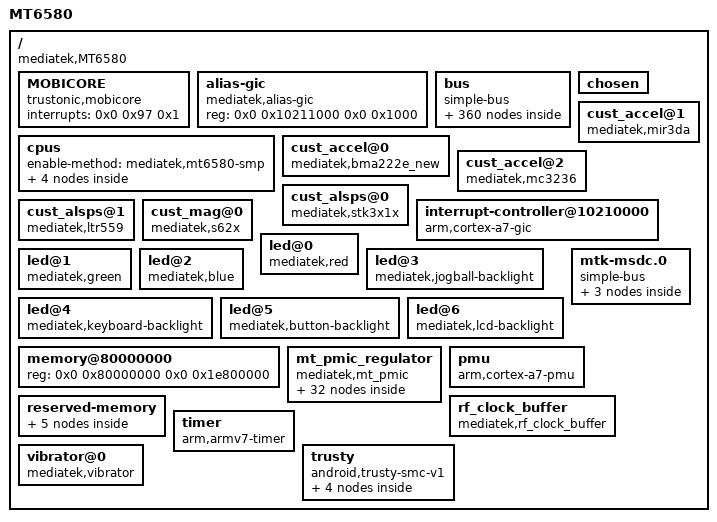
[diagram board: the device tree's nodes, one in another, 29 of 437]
/dts-v1/;

/ {
	#address-cells = <0x2>;
	#size-cells = <0x2>;
	compatible = "mediatek,MT6580";
	interrupt-parent = <0x1>;
	model = "MT6580";

	MOBICORE {
		compatible = "trustonic,mobicore";
		interrupts = <0x0 0x97 0x1>;
	};

	alias-gic {
		compatible = "mediatek,alias-gic";
		reg = <0x0 0x10211000 0x0 0x1000>;
	};

	bus {
		#address-cells = <0x1>;
		#size-cells = <0x1>;
		compatible = "simple-bus";
		ranges = <0x0 0x0 0x0 0xffffffff>;

		AES@0x1000E000 {
			compatible = "mediatek,AES";
			reg = <0x1000e000 0x1000>;
		};

		AHB_MOM@0x11150000 {
			compatible = "mediatek,AHB_MOM";
			reg = <0x11150000 0x10000>;
		};

		APMIXED@0x10018000 {
			compatible = "mediatek,APMIXED";
			reg = <0x10018000 0x1000>;
		};

		APXGPT@0x10008000 {
			clock-frequency = <0xc65d40>;
			compatible = "mediatek,APXGPT";
			interrupts = <0x0 0x5c 0x8>;
			reg = <0x10008000 0x1000>;
		};

		AP_DMA_UART0_RX@0x11000500 {
			compatible = "mediatek,AP_DMA_UART0_RX";
			interrupts = <0x0 0x39 0x8>;
			reg = <0x11000500 0x80>;
		};

		AP_DMA_UART0_TX@0x11000480 {
			compatible = "mediatek,AP_DMA_UART0_TX";
			interrupts = <0x0 0x38 0x8>;
			reg = <0x11000480 0x80>;
		};

		AP_DMA_UART1_RX@0x11000600 {
			compatible = "mediatek,AP_DMA_UART1_RX";
			interrupts = <0x0 0x3b 0x8>;
			reg = <0x11000600 0x80>;
		};

		AP_DMA_UART1_TX@0x11000580 {
			compatible = "mediatek,AP_DMA_UART1_TX";
			interrupts = <0x0 0x3a 0x8>;
			reg = <0x11000580 0x80>;
		};

		AP_UART0@0x11005000 {
			cell-index = <0x0>;
			compatible = "mediatek,AP_UART0";
			interrupts = <0x0 0x2c 0x8>;
			reg = <0x11005000 0x1000>;
		};

		AP_UART1@0x11006000 {
			cell-index = <0x1>;
			compatible = "mediatek,AP_UART1";
			interrupts = <0x0 0x2d 0x8>;
			reg = <0x11006000 0x1000>;
		};

		BAT_NOTIFY {
			compatible = "mediatek,bat_notify";
		};

		BTCVSD@0x18000000 {
			compatible = "mediatek,audio_bt_cvsd";
			interrupts = <0x0 0x99 0x8>;
			offset = <0xc00 0x2 0xfd0 0xfd4 0xfd8>;
			reg = <0x10001000 0x1000 0x18000000 0x10000 0x18080000 0x8000>;
		};

		CAM_0@0x15004000 {
			compatible = "mediatek,CAM_0";
			interrupts = <0x0 0x8b 0x8>;
			reg = <0x15004000 0x1000>;
		};

		CAM_1@0x15005000 {
			compatible = "mediatek,CAM_1";
			reg = <0x15005000 0x1000>;
		};

		DBGSYS_CPU@0x10160000 {
			compatible = "mediatek,DBGSYS_CPU";
			reg = <0x10160000 0x20000>;
		};

		DBGSYS_CTI@0x10112000 {
			compatible = "mediatek,DBGSYS_CTI";
			reg = <0x10112000 0x1000>;
		};

		DBGSYS_DAPROM@0x10110000 {
			compatible = "mediatek,DBGSYS_DAPROM";
			reg = <0x10110000 0x1000>;
		};

		DBGSYS_DEM@0x1011A000 {
			compatible = "mediatek,DBGSYS_DEM";
			reg = <0x1011a000 0x1000>;
		};

		DBGSYS_MDSYS@0x10120000 {
			compatible = "mediatek,DBGSYS_MDSYS";
			reg = <0x10120000 0x10000>;
		};

		DDRPHY@0x10208000 {
			compatible = "mediatek,DDRPHY";
			reg = <0x10208000 0x1000>;
		};

		DEVAPC@0x10204000 {
			compatible = "mediatek,DEVAPC";
			interrupts = <0x0 0x4a 0x8>;
			reg = <0x10204000 0x1000>;
		};

		DEVAPC_AO@0x10010000 {
			compatible = "mediatek,DEVAPC_AO";
			reg = <0x10010000 0x1000>;
		};

		DISPSYS@0x14007000 {
			compatible = "mediatek,DISPSYS";
			interrupts = <0x0 0x0 0x8 0x0 0x77 0x8 0x0 0x0 0x8 0x0 0x79 0x8 0x0 0x0 0x8 0x0 0x7b 0x8 0x0 0x7c 0x8 0x0 0x0 0x8 0x0 0x7e 0x8 0x0 0x7f 0x8 0x0 0x80 0x8 0x0 0x0 0x8 0x0 0x82 0x8 0x0 0x0 0x8 0x0 0x0 0x8 0x0 0x70 0x8 0x0 0x0 0x8 0x0 0x0 0x8 0x0 0x0 0x8>;
			reg = <0x14000000 0x1000 0x14007000 0x1000 0x14008000 0x1000 0x14009000 0x1000 0x1400a000 0x1000 0x1400b000 0x1000 0x1400c000 0x1000 0x1400d000 0x1000 0x1400e000 0x1000 0x1400f000 0x1000 0x14010000 0x1000 0x14011000 0x1000 0x14012000 0x1000 0x14013000 0x1000 0x1100f000 0x1000 0x14015000 0x1000 0x14016000 0x1000 0x14017000 0x1000 0x14018000 0x1000>;
		};

		DISP_AAL@0x1400E000 {
			compatible = "mediatek,DISP_AAL";
			interrupts = <0x0 0x7e 0x8>;
			reg = <0x1400e000 0x1000>;
		};

		DISP_CCORR@0x1400D000 {
			compatible = "mediatek,DISP_CCORR";
			reg = <0x1400d000 0x1000>;
		};

		DISP_COLOR@0x1400C000 {
			compatible = "mediatek,DISP_COLOR";
			interrupts = <0x0 0x7c 0x8>;
			reg = <0x1400c000 0x1000>;
		};

		DISP_DITHER@0x14010000 {
			compatible = "mediatek,DISP_DITHER";
			interrupts = <0x0 0x80 0x8>;
			reg = <0x14010000 0x1000>;
		};

		DISP_GAMMA@0x1400F000 {
			compatible = "mediatek,DISP_GAMMA";
			interrupts = <0x0 0x7f 0x8>;
			reg = <0x1400f000 0x1000>;
		};

		DISP_OVL0@0x14007000 {
			compatible = "mediatek,DISP_OVL0";
			interrupts = <0x0 0x77 0x8>;
			reg = <0x14007000 0x1000>;
		};

		DISP_OVL1@0x14008000 {
			compatible = "mediatek,DISP_OVL1";
			reg = <0x14008000 0x1000>;
		};

		DISP_PWM@0x1100F000 {
			compatible = "mediatek,DISP_PWM";
			interrupts = <0x0 0x21 0x8>;
			reg = <0x1100f000 0x1000>;
		};

		DISP_RDMA0@0x14009000 {
			compatible = "mediatek,DISP_RDMA0";
			interrupts = <0x0 0x79 0x8>;
			reg = <0x14009000 0x1000>;
		};

		DISP_RDMA1@0x1400A000 {
			compatible = "mediatek,DISP_RDMA1";
			reg = <0x1400a000 0x1000>;
		};

		DISP_UFOE@0x14011000 {
			compatible = "mediatek,DISP_UFOE";
			reg = <0x14011000 0x1000>;
		};

		DISP_WDMA@0x1400B000 {
			compatible = "mediatek,DISP_WDMA";
			interrupts = <0x0 0x7b 0x8>;
			reg = <0x1400b000 0x1000>;
		};

		DPI@0x14013000 {
			compatible = "mediatek,DPI";
			reg = <0x14013000 0x1000>;
		};

		DRAMC0@0x10207000 {
			compatible = "mediatek,DRAMC0";
			reg = <0x10207000 0x1000>;
		};

		DRAMC_NAO@0x10206000 {
			compatible = "mediatek,DRAMC_NAO";
			reg = <0x10206000 0x1000>;
		};

		DSI@0x14012000 {
			compatible = "mediatek,DSI";
			reg = <0x14012000 0x1000>;
		};

		EFUSEC@0x10009000 {
			compatible = "mediatek,EFUSEC";
			reg = <0x10009000 0x1000>;
		};

		EMI@0x10205000 {
			compatible = "mediatek,EMI";
			interrupts = <0x0 0x4c 0x4>;
			reg = <0x10205000 0x1000>;
		};

		FHCTL@0x11004000 {
			compatible = "mediatek,FHCTL";
			reg = <0x11004000 0x1000>;
		};

		G3D_CONFIG@0x13000000 {
			compatible = "mediatek,G3D_CONFIG";
			reg = <0x13000000 0x1000>;
		};

		IMGSYS_CONFIG@0x15000000 {
			compatible = "mediatek,IMGSYS_CONFIG";
			reg = <0x15000000 0x1000>;
		};

		INFRACFG@0x10201000 {
			compatible = "mediatek,INFRACFG";
			reg = <0x10201000 0x1000>;
		};

		INFRACFG_AO@0x10001000 {
			compatible = "mediatek,INFRACFG_AO";
			reg = <0x10001000 0x1000>;
		};

		INFRA_MBIST@0x10012000 {
			compatible = "mediatek,INFRA_MBIST";
			reg = <0x10012000 0x1000>;
		};

		IOCFG_B@0x10015000 {
			compatible = "mediatek,IOCFG_B";
			reg = <0x10015000 0x1000>;
		};

		IOCFG_L@0x10016000 {
			compatible = "mediatek,IOCFG_L";
			reg = <0x10016000 0x1000>;
		};

		IOCFG_R@0x10017000 {
			compatible = "mediatek,IOCFG_R";
			reg = <0x10017000 0x1000>;
		};

		IOCFG_T@0x10014000 {
			compatible = "mediatek,IOCFG_T";
			reg = <0x10014000 0x1000>;
		};

		ISPSYS@0x15000000 {
			compatible = "mediatek,ISPSYS";
			interrupts = <0x0 0x8e 0x8 0x0 0x8b 0x8>;
			reg = <0x15004000 0x9000 0x15000000 0x10000 0x10011000 0x4000 0x10017000 0x1000>;
		};

		ISP_PIPEM@0x15000000 {
			compatible = "mediatek,ISP_PIPEM";
		};

		ISP_SYSR@0x15000000 {
			compatible = "mediatek,ISP_SYSR";
		};

		MALI@0x13010000 {
			compatible = "mediatek,MALI";
			reg = <0x13010000 0x10000>;
		};

		MCUCFG@0x10200000 {
			compatible = "mediatek,MCUCFG";
			reg = <0x10200000 0x1000>;
		};

		MCUCFG_BIU@0x1020D000 {
			compatible = "mediatek,MCUCFG_BIU";
			reg = <0x1020d000 0x1000>;
		};

		MCUSYS_CFGREG@0x1020000 {
			compatible = "mediatek,MCUSYS_CFGREG_BASE";
			reg = <0x1020000 0x200>;
		};

		MDI@0x11160000 {
			compatible = "mediatek,MDI";
			reg = <0x11160000 0x10000>;
		};

		MIPI_CONFG@0x10011000 {
			compatible = "mediatek,MIPI_CONFG";
			reg = <0x10011000 0x1000>;
		};

		MIPI_TX_CONFIG@0x14018000 {
			compatible = "mediatek,MIPI_TX_CONFIG";
			reg = <0x14018000 0x1000>;
		};

		MM_MUTEX@0x14015000 {
			compatible = "mediatek,MM_MUTEX";
			interrupts = <0x0 0x70 0x8>;
			reg = <0x14015000 0x1000>;
		};

		NFI@0x11001000 {
			compatible = "mediatek,NFI";
			interrupts = <0x0 0x2f 0x8>;
			reg = <0x11001000 0x1000>;
		};

		NFIECC@0x11002000 {
			compatible = "mediatek,NFIECC";
			interrupts = <0x0 0x2e 0x8>;
			reg = <0x11002000 0x1000>;
		};

		PERICFG@0x10003000 {
			compatible = "mediatek,PERICFG";
			reg = <0x10003000 0x1000>;
		};

		PTP_FSM@0x1100D000 {
			compatible = "mediatek,PTP_FSM";
			interrupts = <0x0 0x2b 0x8>;
			reg = <0x1100d000 0x1000>;
		};

		PWM@0x11008000 {
			compatible = "mediatek,PWM";
			interrupts = <0x0 0x24 0x8>;
			reg = <0x11008000 0x1000>;
		};

		PWRAP@0x1000F000 {
			compatible = "mediatek,PWRAP";
			interrupts = <0x0 0x6c 0x0>;
			reg = <0x1000f000 0x1000>;
		};

		RESERVED@0x10004000 {
			compatible = "mediatek,RESERVED";
			reg = <0x10004000 0x1000>;
		};

		RESERVED@0x10013000 {
			compatible = "mediatek,RESERVED";
			reg = <0x10013000 0x1000>;
		};

		SLEEP@0x10006000 {
			compatible = "mediatek,SLEEP";
			interrupts = <0x0 0x58 0x8 0x0 0x59 0x8 0x0 0x5a 0x8 0x0 0x5b 0x8>;
			reg = <0x10006000 0x1000>;
		};

		SMI_COMMON@0x14017000 {
			compatible = "mediatek,SMI_COMMON";
			reg = <0x14017000 0x1000 0x14016000 0x1000 0x15001000 0x1000>;
		};

		SMI_LARB0@0x14016000 {
			compatible = "mediatek,SMI_LARB0";
			interrupts = <0x0 0x85 0x8>;
			reg = <0x14016000 0x1000>;
		};

		SMI_LARB1@0x15001000 {
			compatible = "mediatek,SMI_LARB1";
			interrupts = <0x0 0x88 0x8>;
			reg = <0x15001000 0x1000>;
		};

		SRAMROM@0x10209000 {
			compatible = "mediatek,SRAMROM";
			reg = <0x10209000 0x1000>;
		};

		THERM_CTRL@0x1100D000 {
			compatible = "mediatek,THERM_CTRL";
			interrupts = <0x0 0x25 0x8>;
			reg = <0x1100d000 0x1000>;
		};

		TOPCKGEN@0x10000000 {
			compatible = "mediatek,TOPCKGEN";
			reg = <0x10000000 0x1000>;
		};

		TOPRGU@0x10007000 {
			compatible = "mediatek,TOPRGU";
			interrupts = <0x0 0x9d 0x2>;
			reg = <0x10007000 0x1000>;
		};

		TRNG@0x1020C000 {
			compatible = "mediatek,TRNG";
			interrupts = <0x0 0x57 0x8>;
			reg = <0x1020c000 0x1000>;
		};

		USB0@0x11100000 {
			cell-index = <0x0>;
			compatible = "mediatek,USB0";
			dma = <0x1>;
			dma_channels = <0x8>;
			drvvbus_gpio = <0x19 0x0>;
			dyn_fifo = <0x1>;
			iddig_gpio = <0x10 0x6>;
			interrupts = <0x0 0x20 0x8>;
			mode = <0x2>;
			multipoint = <0x1>;
			num_eps = <0x10>;
			pinctrl-0 = <0x1f>;
			pinctrl-1 = <0x20>;
			pinctrl-2 = <0x21>;
			pinctrl-3 = <0x22>;
			pinctrl-4 = <0x23>;
			pinctrl-5 = <0x24>;
			pinctrl-6 = <0x25>;
			pinctrl-7 = <0x26>;
			pinctrl-names = "usb_default", "iddig_irq_init", "drvvbus_init", "drvvbus_low", "drvvbus_high", "otgusden_init", "otgusben_low", "otgusben_high";
			reg = <0x11100000 0x10000 0x11110000 0x10000>;
			soft_con = <0x1>;
			status = "okay";

			usbiddig {
				compatible = "mediatek,usb_iddig_eint";
				debounce = <0x10 0x0>;
				interrupt-parent = <0xc>;
				interrupts = <0x10 0x8>;
				status = "okay";
			};
		};

		VDEC@0x1500B000 {
			compatible = "mediatek,VDEC";
			interrupts = <0x0 0x89 0x8>;
			reg = <0x1500b000 0x1000>;
		};

		VENC@0x15009000 {
			compatible = "mediatek,VENC";
			interrupts = <0x0 0x8a 0x8>;
			reg = <0x15009000 0x1000>;
		};

		WIFI@0x180F0000 {
			compatible = "mediatek,WIFI";
			interrupts = <0x0 0x9b 0x8>;
			reg = <0x180f0000 0x5c>;
		};

		accdet {
			accdet-mic-mode = <0x1>;
			accdet-mic-vol = <0x7>;
			accdet-plugout-debounce = <0x14>;
			compatible = "mediatek,mt6580-accdet";
			debounce = <0x4 0x3e800>;
			headset-four-key-threshold = <0x0 0x3c 0x7e 0xc9 0x1c2>;
			headset-mode-setting = <0x500 0x200 0x1 0x1f0 0x800 0x800 0x20>;
			headset-three-key-threshold = <0x0 0x5a 0xf0 0x1f4>;
			interrupt-parent = <0xc>;
			interrupts = <0x4 0x8>;
			pinctrl-0 = <0x15>;
			pinctrl-1 = <0x16>;
			pinctrl-names = "default", "state_eint_as_int";
			status = "okay";
		};

		activity@0 {
			compatible = "mediatek,activity";
		};

		adc_hw@11003000 {
			compatible = "mediatek,mt6735-auxadc";
			interrupts = <0x0 0x23 0x2>;
			reg = <0x11003000 0x1000>;

			adc_channel@ {
				compatible = "mediatek,adc_channel";
				mediatek,temperature0 = <0x0>;
				mediatek,temperature1 = <0x1>;
				status = "okay";
			};
		};

		als {
			compatible = "mediatek, als-eint";
			debounce = <0x6 0x7d00>;
			interrupt-parent = <0xc>;
			interrupts = <0x6 0x8>;
			status = "okay";
		};

		als_ps@0 {
			compatible = "mediatek,als_ps";
			pinctrl-0 = <0x47>;
			pinctrl-1 = <0x48>;
			pinctrl-names = "pin_default", "pin_cfg";
			status = "okay";
		};

		ap_ccif0@1000C000 {
			compatible = "mediatek,ap_ccif0";
			interrupts = <0x0 0x5d 0x8 0x0 0x98 0x2>;
			mediatek,ccif_capability = <0x2>;
			mediatek,md_smem_size = <0x200000>;
			reg = <0x1000c000 0x1000 0x1000d000 0x1000>;
		};

		audio@11140000 {
			compatible = "mediatek,audio";
			interrupts = <0x0 0x50 0x8>;
			reg = <0x11140000 0x10000>;
		};

		barometer@0 {
			compatible = "mediatek,barometer";
		};

		bat_comm {
			ac_charger_current = <0x15f90>;
			bat_low_temp_protect_enable = <0x0>;
			charging_host_charger_current = <0xfde8>;
			compatible = "mediatek,battery";
			fg_meter_resistance = <0x0>;
			high_battery_voltage_support = <0x0>;
			non_std_ac_charger_current = <0xfde8>;
			npercent_tracking_time = <0x14>;
			onehundred_percent_tracking_time = <0xa>;
			r_bat_sense = <0x4>;
			r_charger_1 = <0x14a>;
			r_charger_2 = <0x27>;
			r_i_sense = <0x4>;
			sync_to_real_tracking_time = <0x3c>;
			temperature_t = <0xff>;
			temperature_t0 = <0x6e>;
			temperature_t1 = <0x0>;
			temperature_t2 = <0x19>;
			temperature_t3 = <0x32>;
			usb_charger_current = <0xfde8>;
			v_0percent_tracking = <0xd48>;
			v_charger_enable = <0x0>;
			v_charger_max = <0x1964>;
			v_charger_min = <0x1130>;
		};

		bat_meter {
			aging_tuning_value = <0x67>;
			batt_temperature_table = <0xffffffec 0x10a8d 0xfffffff1 0xd192 0xfffffff6 0xa60a 0xfffffffb 0x8464 0x0 0x6a53 0x5 0x5605 0xa 0x4606 0xf 0x3952 0x14 0x2f31 0x19 0x2710 0x1e 0x207b 0x23 0x1b24 0x28 0x16ca 0x2d 0x1335 0x32 0x1041 0x37 0xdcf 0x3c 0xbc6>;
			batt_temperature_table_num = <0x11>;
			battery_profile_t0 = <0x0 0x1048 0x1 0x102b 0x2 0x1018 0x3 0x100a 0x4 0xffe 0x5 0xff5 0x6 0xfec 0x7 0xfe5 0x8 0xfdf 0x9 0xfd8 0xa 0xfd3 0xb 0xfce 0xc 0xfca 0xd 0xfc5 0xe 0xfc1 0xf 0xfbd 0x10 0xfb9 0x11 0xfb5 0x12 0xfb1 0x13 0xfad 0x14 0xfaa 0x15 0xfa5 0x16 0xfa0 0x17 0xf9c 0x18 0xf98 0x19 0xf93 0x1a 0xf8e 0x1b 0xf89 0x1c 0xf83 0x1d 0xf7e 0x1e 0xf79 0x1f 0xf73 0x20 0xf6d 0x21 0xf67 0x22 0xf61 0x23 0xf5a 0x24 0xf54 0x25 0xf4d 0x26 0xf46 0x27 0xf3f 0x28 0xf3a 0x29 0xf33 0x2a 0xf2d 0x2b 0xf27 0x2c 0xf21 0x2d 0xf1b 0x2e 0xf16 0x2f 0xf11 0x30 0xf0c 0x31 0xf07 0x33 0xf01 0x34 0xefe 0x35 0xef9 0x36 0xef4 0x37 0xeef 0x38 0xeeb 0x39 0xee7 0x3a 0xee2 0x3b 0xedd 0x3c 0xed8 0x3d 0xed4 0x3e 0xecf 0x3f 0xec9 0x40 0xec4 0x41 0xebf 0x42 0xeba 0x43 0xeb4 0x44 0xeae 0x45 0xea7 0x46 0xea1 0x47 0xe99 0x48 0xe92 0x49 0xe8a 0x4a 0xe83 0x4b 0xe7a 0x4c 0xe71 0x4d 0xe68 0x4e 0xe60 0x4f 0xe57 0x50 0xe4f 0x51 0xe46 0x52 0xe3e 0x53 0xe36 0x54 0xe2f 0x55 0xe27 0x56 0xe20 0x57 0xe18 0x58 0xe12 0x59 0xe0b 0x5a 0xe04 0x5b 0xdfd 0x5c 0xdf6 0x5d 0xdef 0x5e 0xde8 0x5f 0xde1 0x60 0xdd9 0x61 0xdd0 0x62 0xdc8 0x63 0xdc0 0x64 0xdb5 0x65 0xdac>;
			battery_profile_t0_num = <0x65>;
			battery_profile_t1 = <0x0 0x1048 0x1 0x102b 0x2 0x1018 0x3 0x100a 0x4 0xffe 0x5 0xff5 0x6 0xfec 0x7 0xfe5 0x8 0xfdf 0x9 0xfd8 0xa 0xfd3 0xb 0xfce 0xc 0xfca 0xd 0xfc5 0xe 0xfc1 0xf 0xfbd 0x10 0xfb9 0x11 0xfb5 0x12 0xfb1 0x13 0xfad 0x14 0xfaa 0x15 0xfa5 0x16 0xfa0 0x17 0xf9c 0x18 0xf98 0x19 0xf93 0x1a 0xf8e 0x1b 0xf89 0x1c 0xf83 0x1d 0xf7e 0x1e 0xf79 0x1f 0xf73 0x20 0xf6d 0x21 0xf67 0x22 0xf61 0x23 0xf5a 0x24 0xf54 0x25 0xf4d 0x26 0xf46 0x27 0xf3f 0x28 0xf3a 0x29 0xf33 0x2a 0xf2d 0x2b 0xf27 0x2c 0xf21 0x2d 0xf1b 0x2e 0xf16 0x2f 0xf11 0x30 0xf0c 0x31 0xf07 0x33 0xf01 0x34 0xefe 0x35 0xef9 0x36 0xef4 0x37 0xeef 0x38 0xeeb 0x39 0xee7 0x3a 0xee2 0x3b 0xedd 0x3c 0xed8 0x3d 0xed4 0x3e 0xecf 0x3f 0xec9 0x40 0xec4 0x41 0xebf 0x42 0xeba 0x43 0xeb4 0x44 0xeae 0x45 0xea7 0x46 0xea1 0x47 0xe99 0x48 0xe92 0x49 0xe8a 0x4a 0xe83 0x4b 0xe7a 0x4c 0xe71 0x4d 0xe68 0x4e 0xe60 0x4f 0xe57 0x50 0xe4f 0x51 0xe46 0x52 0xe3e 0x53 0xe36 0x54 0xe2f 0x55 0xe27 0x56 0xe20 0x57 0xe18 0x58 0xe12 0x59 0xe0b 0x5a 0xe04 0x5b 0xdfd 0x5c 0xdf6 0x5d 0xdef 0x5e 0xde8 0x5f 0xde1 0x60 0xdd9 0x61 0xdd0 0x62 0xdc8 0x63 0xdc0 0x64 0xdb5 0x65 0xdac>;
			battery_profile_t1_num = <0x65>;
			battery_profile_t2 = <0x0 0x1048 0x1 0x102b 0x2 0x1018 0x3 0x100a 0x4 0xffe 0x5 0xff5 0x6 0xfec 0x7 0xfe5 0x8 0xfdf 0x9 0xfd8 0xa 0xfd3 0xb 0xfce 0xc 0xfca 0xd 0xfc5 0xe 0xfc1 0xf 0xfbd 0x10 0xfb9 0x11 0xfb5 0x12 0xfb1 0x13 0xfad 0x14 0xfaa 0x15 0xfa5 0x16 0xfa0 0x17 0xf9c 0x18 0xf98 0x19 0xf93 0x1a 0xf8e 0x1b 0xf89 0x1c 0xf83 0x1d 0xf7e 0x1e 0xf79 0x1f 0xf73 0x20 0xf6d 0x21 0xf67 0x22 0xf61 0x23 0xf5a 0x24 0xf54 0x25 0xf4d 0x26 0xf46 0x27 0xf3f 0x28 0xf3a 0x29 0xf33 0x2a 0xf2d 0x2b 0xf27 0x2c 0xf21 0x2d 0xf1b 0x2e 0xf16 0x2f 0xf11 0x30 0xf0c 0x31 0xf07 0x33 0xf01 0x34 0xefe 0x35 0xef9 0x36 0xef4 0x37 0xeef 0x38 0xeeb 0x39 0xee7 0x3a 0xee2 0x3b 0xedd 0x3c 0xed8 0x3d 0xed4 0x3e 0xecf 0x3f 0xec9 0x40 0xec4 0x41 0xebf 0x42 0xeba 0x43 0xeb4 0x44 0xeae 0x45 0xea7 0x46 0xea1 0x47 0xe99 0x48 0xe92 0x49 0xe8a 0x4a 0xe83 0x4b 0xe7a 0x4c 0xe71 0x4d 0xe68 0x4e 0xe60 0x4f 0xe57 0x50 0xe4f 0x51 0xe46 0x52 0xe3e 0x53 0xe36 0x54 0xe2f 0x55 0xe27 0x56 0xe20 0x57 0xe18 0x58 0xe12 0x59 0xe0b 0x5a 0xe04 0x5b 0xdfd 0x5c 0xdf6 0x5d 0xdef 0x5e 0xde8 0x5f 0xde1 0x60 0xdd9 0x61 0xdd0 0x62 0xdc8 0x63 0xdc0 0x64 0xdb5 0x65 0xdac>;
			battery_profile_t2_num = <0x65>;
			battery_profile_t3 = <0x0 0x1048 0x1 0x102b 0x2 0x1018 0x3 0x100a 0x4 0xffe 0x5 0xff5 0x6 0xfec 0x7 0xfe5 0x8 0xfdf 0x9 0xfd8 0xa 0xfd3 0xb 0xfce 0xc 0xfca 0xd 0xfc5 0xe 0xfc1 0xf 0xfbd 0x10 0xfb9 0x11 0xfb5 0x12 0xfb1 0x13 0xfad 0x14 0xfaa 0x15 0xfa5 0x16 0xfa0 0x17 0xf9c 0x18 0xf98 0x19 0xf93 0x1a 0xf8e 0x1b 0xf89 0x1c 0xf83 0x1d 0xf7e 0x1e 0xf79 0x1f 0xf73 0x20 0xf6d 0x21 0xf67 0x22 0xf61 0x23 0xf5a 0x24 0xf54 0x25 0xf4d 0x26 0xf46 0x27 0xf3f 0x28 0xf3a 0x29 0xf33 0x2a 0xf2d 0x2b 0xf27 0x2c 0xf21 0x2d 0xf1b 0x2e 0xf16 0x2f 0xf11 0x30 0xf0c 0x31 0xf07 0x33 0xf01 0x34 0xefe 0x35 0xef9 0x36 0xef4 0x37 0xeef 0x38 0xeeb 0x39 0xee7 0x3a 0xee2 0x3b 0xedd 0x3c 0xed8 0x3d 0xed4 0x3e 0xecf 0x3f 0xec9 0x40 0xec4 0x41 0xebf 0x42 0xeba 0x43 0xeb4 0x44 0xeae 0x45 0xea7 0x46 0xea1 0x47 0xe99 0x48 0xe92 0x49 0xe8a 0x4a 0xe83 0x4b 0xe7a 0x4c 0xe71 0x4d 0xe68 0x4e 0xe60 0x4f 0xe57 0x50 0xe4f 0x51 0xe46 0x52 0xe3e 0x53 0xe36 0x54 0xe2f 0x55 0xe27 0x56 0xe20 0x57 0xe18 0x58 0xe12 0x59 0xe0b 0x5a 0xe04 0x5b 0xdfd 0x5c 0xdf6 0x5d 0xdef 0x5e 0xde8 0x5f 0xde1 0x60 0xdd9 0x61 0xdd0 0x62 0xdc8 0x63 0xdc0 0x64 0xdb5 0x65 0xdac>;
			battery_profile_t3_num = <0x65>;
			car_tune_value = <0x64>;
			change_tracking_point = <0x1>;
			close_poweroff_wakeup_period = <0x1e>;
			compatible = "mediatek,bat_meter";
			current_detect_r_fg = <0xa>;
			cust_hw_cc = <0x0>;
			cust_poweron_delta_capacity_tolrance = <0x28>;
			cust_poweron_delta_hw_sw_ocv_capacity_tolrance = <0xa>;
			cust_poweron_delta_vbat_tolrance = <0x1e>;
			cust_poweron_low_capacity_tolrance = <0x5>;
			cust_poweron_max_vbat_tolrance = <0x5a>;
			cust_r_fg_offset = <0x0>;
			cust_r_sense = <0x64>;
			cust_tracking_point = <0x1>;
			fg_vbat_average_size = <0x12>;
			fixed_tbat_25 = <0x0>;
			low_power_wakeup_period = <0x12c>;
			minerroroffset = <0x3e8>;
			normal_wakeup_period = <0x1518>;
			oam_d5 = <0x1>;
			ocv_board_compesate = <0x0>;
			q_max_neg_10 = <0x1162>;
			q_max_neg_10_h_current = <0x10cc>;
			q_max_pos_0 = <0x1162>;
			q_max_pos_0_h_current = <0x10cc>;
			q_max_pos_25 = <0x1162>;
			q_max_pos_25_h_current = <0x10cc>;
			q_max_pos_50 = <0x1162>;
			q_max_pos_50_h_current = <0x10cc>;
			r_fg_board_base = <0x3e8>;
			r_fg_board_slope = <0x3e8>;
			r_fg_value = <0x0>;
			r_profile_t0 = <0x46 0x105c 0x46 0x102b 0x46 0x1018 0x46 0x100a 0x46 0xffe 0x46 0xff5 0x46 0xfec 0x46 0xfe5 0x46 0xfdf 0x46 0xfd8 0x46 0xfd3 0x46 0xfce 0x46 0xfca 0x46 0xfc5 0x46 0xfc1 0x46 0xfbd 0x46 0xfb9 0x46 0xfb5 0x46 0xfb1 0x46 0xfad 0x46 0xfaa 0x46 0xfa5 0x46 0xfa0 0x46 0xf9c 0x46 0xf98 0x46 0xf93 0x46 0xf8e 0x46 0xf89 0x46 0xf83 0x46 0xf7e 0x46 0xf79 0x46 0xf73 0x46 0xf6d 0x46 0xf67 0x46 0xf61 0x46 0xf5a 0x46 0xf54 0x46 0xf4d 0x46 0xf46 0x46 0xf3f 0x46 0xf3a 0x46 0xf33 0x46 0xf2d 0x46 0xf27 0x46 0xf21 0x46 0xf1b 0x46 0xf16 0x46 0xf11 0x46 0xf0c 0x46 0xf07 0x46 0xf01 0x46 0xefe 0x46 0xef9 0x46 0xef4 0x46 0xeef 0x46 0xeeb 0x46 0xee7 0x46 0xee2 0x46 0xedd 0x46 0xed8 0x46 0xed4 0x46 0xecf 0x46 0xec9 0x46 0xec4 0x46 0xebf 0x46 0xeba 0x46 0xeb4 0x46 0xeae 0x46 0xea7 0x46 0xea1 0x46 0xe99 0x46 0xe92 0x46 0xe8a 0x46 0xe83 0x46 0xe7a 0x46 0xe71 0x46 0xe68 0x46 0xe60 0x46 0xe57 0x46 0xe4f 0x46 0xe46 0x46 0xe3e 0x46 0xe36 0x46 0xe2f 0x46 0xe27 0x46 0xe20 0x46 0xe18 0x46 0xe12 0x46 0xe0b 0x46 0xe04 0x46 0xdfd 0x46 0xdf6 0x46 0xdef 0x46 0xde8 0x46 0xde1 0x46 0xdd9 0x46 0xdd0 0x46 0xdc8 0x46 0xdc0 0x46 0xdb5 0x46 0xdac>;
			r_profile_t0_num = <0x65>;
			r_profile_t1 = <0x46 0x105c 0x46 0x102b 0x46 0x1018 0x46 0x100a 0x46 0xffe 0x46 0xff5 0x46 0xfec 0x46 0xfe5 0x46 0xfdf 0x46 0xfd8 0x46 0xfd3 0x46 0xfce 0x46 0xfca 0x46 0xfc5 0x46 0xfc1 0x46 0xfbd 0x46 0xfb9 0x46 0xfb5 0x46 0xfb1 0x46 0xfad 0x46 0xfaa 0x46 0xfa5 0x46 0xfa0 0x46 0xf9c 0x46 0xf98 0x46 0xf93 0x46 0xf8e 0x46 0xf89 0x46 0xf83 0x46 0xf7e 0x46 0xf79 0x46 0xf73 0x46 0xf6d 0x46 0xf67 0x46 0xf61 0x46 0xf5a 0x46 0xf54 0x46 0xf4d 0x46 0xf46 0x46 0xf3f 0x46 0xf3a 0x46 0xf33 0x46 0xf2d 0x46 0xf27 0x46 0xf21 0x46 0xf1b 0x46 0xf16 0x46 0xf11 0x46 0xf0c 0x46 0xf07 0x46 0xf01 0x46 0xefe 0x46 0xef9 0x46 0xef4 0x46 0xeef 0x46 0xeeb 0x46 0xee7 0x46 0xee2 0x46 0xedd 0x46 0xed8 0x46 0xed4 0x46 0xecf 0x46 0xec9 0x46 0xec4 0x46 0xebf 0x46 0xeba 0x46 0xeb4 0x46 0xeae 0x46 0xea7 0x46 0xea1 0x46 0xe99 0x46 0xe92 0x46 0xe8a 0x46 0xe83 0x46 0xe7a 0x46 0xe71 0x46 0xe68 0x46 0xe60 0x46 0xe57 0x46 0xe4f 0x46 0xe46 0x46 0xe3e 0x46 0xe36 0x46 0xe2f 0x46 0xe27 0x46 0xe20 0x46 0xe18 0x46 0xe12 0x46 0xe0b 0x46 0xe04 0x46 0xdfd 0x46 0xdf6 0x46 0xdef 0x46 0xde8 0x46 0xde1 0x46 0xdd9 0x46 0xdd0 0x46 0xdc8 0x46 0xdc0 0x46 0xdb5 0x46 0xdac>;
			r_profile_t1_num = <0x65>;
			r_profile_t2 = <0x46 0x105c 0x46 0x102b 0x46 0x1018 0x46 0x100a 0x46 0xffe 0x46 0xff5 0x46 0xfec 0x46 0xfe5 0x46 0xfdf 0x46 0xfd8 0x46 0xfd3 0x46 0xfce 0x46 0xfca 0x46 0xfc5 0x46 0xfc1 0x46 0xfbd 0x46 0xfb9 0x46 0xfb5 0x46 0xfb1 0x46 0xfad 0x46 0xfaa 0x46 0xfa5 0x46 0xfa0 0x46 0xf9c 0x46 0xf98 0x46 0xf93 0x46 0xf8e 0x46 0xf89 0x46 0xf83 0x46 0xf7e 0x46 0xf79 0x46 0xf73 0x46 0xf6d 0x46 0xf67 0x46 0xf61 0x46 0xf5a 0x46 0xf54 0x46 0xf4d 0x46 0xf46 0x46 0xf3f 0x46 0xf3a 0x46 0xf33 0x46 0xf2d 0x46 0xf27 0x46 0xf21 0x46 0xf1b 0x46 0xf16 0x46 0xf11 0x46 0xf0c 0x46 0xf07 0x46 0xf01 0x46 0xefe 0x46 0xef9 0x46 0xef4 0x46 0xeef 0x46 0xeeb 0x46 0xee7 0x46 0xee2 0x46 0xedd 0x46 0xed8 0x46 0xed4 0x46 0xecf 0x46 0xec9 0x46 0xec4 0x46 0xebf 0x46 0xeba 0x46 0xeb4 0x46 0xeae 0x46 0xea7 0x46 0xea1 0x46 0xe99 0x46 0xe92 0x46 0xe8a 0x46 0xe83 0x46 0xe7a 0x46 0xe71 0x46 0xe68 0x46 0xe60 0x46 0xe57 0x46 0xe4f 0x46 0xe46 0x46 0xe3e 0x46 0xe36 0x46 0xe2f 0x46 0xe27 0x46 0xe20 0x46 0xe18 0x46 0xe12 0x46 0xe0b 0x46 0xe04 0x46 0xdfd 0x46 0xdf6 0x46 0xdef 0x46 0xde8 0x46 0xde1 0x46 0xdd9 0x46 0xdd0 0x46 0xdc8 0x46 0xdc0 0x46 0xdb5 0x46 0xdac>;
			r_profile_t2_num = <0x65>;
			r_profile_t3 = <0x46 0x105c 0x46 0x102b 0x46 0x1018 0x46 0x100a 0x46 0xffe 0x46 0xff5 0x46 0xfec 0x46 0xfe5 0x46 0xfdf 0x46 0xfd8 0x46 0xfd3 0x46 0xfce 0x46 0xfca 0x46 0xfc5 0x46 0xfc1 0x46 0xfbd 0x46 0xfb9 0x46 0xfb5 0x46 0xfb1 0x46 0xfad 0x46 0xfaa 0x46 0xfa5 0x46 0xfa0 0x46 0xf9c 0x46 0xf98 0x46 0xf93 0x46 0xf8e 0x46 0xf89 0x46 0xf83 0x46 0xf7e 0x46 0xf79 0x46 0xf73 0x46 0xf6d 0x46 0xf67 0x46 0xf61 0x46 0xf5a 0x46 0xf54 0x46 0xf4d 0x46 0xf46 0x46 0xf3f 0x46 0xf3a 0x46 0xf33 0x46 0xf2d 0x46 0xf27 0x46 0xf21 0x46 0xf1b 0x46 0xf16 0x46 0xf11 0x46 0xf0c 0x46 0xf07 0x46 0xf01 0x46 0xefe 0x46 0xef9 0x46 0xef4 0x46 0xeef 0x46 0xeeb 0x46 0xee7 0x46 0xee2 0x46 0xedd 0x46 0xed8 0x46 0xed4 0x46 0xecf 0x46 0xec9 0x46 0xec4 0x46 0xebf 0x46 0xeba 0x46 0xeb4 0x46 0xeae 0x46 0xea7 0x46 0xea1 0x46 0xe99 0x46 0xe92 0x46 0xe8a 0x46 0xe83 0x46 0xe7a 0x46 0xe71 0x46 0xe68 0x46 0xe60 0x46 0xe57 0x46 0xe4f 0x46 0xe46 0x46 0xe3e 0x46 0xe36 0x46 0xe2f 0x46 0xe27 0x46 0xe20 0x46 0xe18 0x46 0xe12 0x46 0xe0b 0x46 0xe04 0x46 0xdfd 0x46 0xdf6 0x46 0xdef 0x46 0xde8 0x46 0xde1 0x46 0xdd9 0x46 0xdd0 0x46 0xdc8 0x46 0xdc0 0x46 0xdb5 0x46 0xdac>;
			r_profile_t3_num = <0x65>;
			rbat_pull_up_d = <0x6978>;
			rbat_pull_up_r = <0x4204>;
			rbat_pull_up_volt = <0x708>;
			vbat_low_power_wakeup = <0xdac>;
			vbat_normal_wakeup = <0xe10>;
		};

		btif@1100e000 {
			compatible = "mediatek,btif";
			interrupts = <0x0 0x43 0x8>;
			reg = <0x1100e000 0x1000>;
		};

		btif_rx@11000400 {
			compatible = "mediatek,btif_rx";
			interrupts = <0x0 0x37 0x8>;
			reg = <0x11000400 0x80>;
		};

		btif_tx@11000380 {
			compatible = "mediatek,btif_tx";
			interrupts = <0x0 0x36 0x8>;
			reg = <0x11000380 0x80>;
		};

		bus_dbg@1020b000 {
			compatible = "mediatek,bus_dbg-v2";
			interrupts = <0x0 0x49 0x8>;
			reg = <0x1020b000 0x1000>;
			two_stage_timeout = <0x1>;
		};

		chipid@08000000 {
			compatible = "mediatek,chipid";
			reg = <0x8000000 0x4 0x8000004 0x4 0x8000008 0x4 0x800000c 0x4>;
		};

		consys@18070000 {
			compatible = "mediatek,mt6580-consys";
			interrupts = <0x0 0x9a 0x8 0x0 0x9c 0x8>;
			pinctrl-0 = <0x1b>;
			pinctrl-1 = <0x1c>;
			pinctrl-2 = <0x1d>;
			pinctrl-3 = <0x1e>;
			pinctrl-names = "default", "gps_lna_state_init", "gps_lna_state_oh", "gps_lna_state_ol";
			reg = <0x18070000 0x200 0x10007000 0x100 0x10000000 0x2000 0x10006000 0x1000 0x10005000 0x1000>;
			status = "okay";
			vcn18-supply = <0x17>;
			vcn28-supply = <0x18>;
			vcn33_bt-supply = <0x19>;
			vcn33_wifi-supply = <0x1a>;
		};

		cpu_dbgapb@10170000 {
			compatible = "mediatek,hw_dbg";
			num = <0x4>;
			reg = <0x10170000 0x2000 0x10172000 0x2000 0x10174000 0x2000 0x10176000 0x2000>;
		};

		dma@0x11000000 {
			compatible = "mediatek,ap_dma";
			interrupts = <0x0 0x30 0x8>;
			reg = <0x11000000 0x1000>;
		};

		dsi_te {
			compatible = "mediatek, dsi_te-eint";
		};

		eintc@1000b000 {
			#interrupt-cells = <0x2>;
			compatible = "mediatek,mt-eic";
			interrupt-controller;
			interrupts = <0x0 0x5e 0x4>;
			linux,phandle = <0xc>;
			mediatek,builtin_entry = <0xb>;
			mediatek,builtin_mapping = <0x0 0x3 0x14 0x1 0x3 0x12 0x7 0x4 0x14 0x8 0x4 0x12 0x9 0x3 0x14 0xa 0x3 0x12 0x18 0x5 0x14 0x19 0x5 0x12 0x4d 0x2 0x14 0x4e 0x2 0x12 0xd 0x1 0x11>;
			mediatek,mapping_table = <0x0 0x0 0x1 0x1 0x2 0x2 0x3 0x3 0x4 0x4 0x5 0x5 0x6 0x6 0x7 0x7 0x8 0x8 0x9 0x9 0xa 0xa 0xb 0xb 0xc 0xc 0xd 0xd 0xe 0xe 0xf 0xf 0x10 0x0 0x11 0x1 0x12 0x2 0x13 0x3 0x14 0x4 0x15 0x5 0x16 0x6 0x17 0x7 0x18 0x8 0x19 0x9 0x1a 0xa 0x1b 0xb 0x1c 0xc 0x1d 0xd 0x1e 0xe 0x1f 0xf 0x20 0x0 0x21 0x1 0x22 0x2 0x23 0x3 0x24 0x4 0x25 0x5 0x26 0x6 0x27 0x7 0x28 0x8 0x29 0x9 0x2a 0xa 0x2b 0xb 0x2c 0xc 0x2d 0xd 0x2e 0xe 0x2f 0xf 0x30 0x0 0x31 0x1 0x32 0x2 0x33 0x3 0x34 0x3 0x35 0x4 0x36 0x5 0x37 0x6 0x38 0x7 0x39 0x8 0x3a 0xa 0x3b 0xb 0x3c 0xc 0x3d 0xd 0x3e 0xe 0x3f 0xf 0x40 0x0 0x41 0x1 0x42 0x2 0x43 0x3 0x44 0x10 0x45 0x4 0x46 0x5 0x47 0x6 0x48 0x7 0x49 0x8 0x4a 0x9 0x4b 0xa 0x4c 0xb 0x4d 0xc 0x4e 0xd 0x51 0x0 0x52 0x1 0x53 0x2 0x54 0x3>;
			mediatek,mapping_table_entry = <0x53>;
			mediatek,max_eint_num = <0x1a>;
			phandle = <0xc>;
			reg = <0x1000b000 0x1000>;

			MD1_SIM1_HOT_PLUG_EINT@0 {
				compatible = "mediatek,MD1_SIM1_HOT_PLUG_EINT-eint";
				debounce = <0x0 0x0>;
				dedicated = <0x0 0x1>;
				interrupts = <0x0 0x4>;
				sockettype = <0x0 0x0>;
				src_pin = <0x0 0x820c078>;
				status = "okay";
			};

			MD1_SIM2_HOT_PLUG_EINT@1 {
				compatible = "mediatek,MD1_SIM2_HOT_PLUG_EINT-eint";
				debounce = <0x1 0x0>;
				dedicated = <0x1 0x1>;
				interrupts = <0x1 0x4>;
				sockettype = <0x1 0x0>;
				src_pin = <0x1 0x820c078>;
				status = "okay";
			};

			pmic@13 {
				compatible = "mediatek, pmic-eint";
				debounce = <0xd 0x3e8>;
				interrupt-parent = <0xc>;
				interrupts = <0xd 0x4>;
			};
		};

		face_down@0 {
			compatible = "mediatek,face_down";
		};

		flashlight {
			compatible = "mediatek,flashlight";
			pinctrl-0 = <0x1b>;
			pinctrl-1 = <0x2e>;
			pinctrl-2 = <0x2f>;
			pinctrl-3 = <0x30>;
			pinctrl-4 = <0x31>;
			pinctrl-names = "default", "enable_high", "enable_low", "mode_high", "mode_low";
			status = "okay";
		};

		flashlightsub {
			compatible = "mediatek,flashlightsub";
		};

		gce@1020a000 {
			apxgpt2_count = <0x10008028>;
			audio_base = <0x11220000 0x12 0xffff0000>;
			buf_underrun_event_0 = <0x30>;
			compatible = "mediatek,gce";
			conn_peri_base = <0x18000000 0x7 0xffff0000>;
			disp_aal_frame_done = <0x20>;
			disp_aal_sof = <0xd>;
			disp_color_frame_done = <0x1f>;
			disp_color_sof = <0xc>;
			disp_dither_base = <0x14010000 0x2 0xffff0000>;
			disp_dither_frame_done = <0x22>;
			disp_dither_sof = <0xf>;
			disp_dsi0_frame_done = <0x25>;
			disp_gamma_frame_done = <0x21>;
			disp_gamma_sof = <0xe>;
			disp_mutex_reg = <0x14015000 0x1000>;
			disp_ovl0_frame_done = <0x19>;
			disp_ovl0_sof = <0x6>;
			disp_pwm0_sof = <0x11>;
			disp_rdma0_frame_done = <0x1b>;
			disp_rdma0_sof = <0x8>;
			disp_wdma0_frame_done = <0x1d>;
			disp_wdma0_sof = <0xa>;
			dsi0_te_event = <0x32>;
			g3d_config_base = <0x13000000 0x0 0xffff0000>;
			gcpu_base = <0x10210000 0xf 0xffff0000>;
			imgsys_base = <0x15000000 0x4 0xffff0000>;
			infra_na3_base = <0x10030000 0xb 0xffff0000>;
			infra_na4_base = <0x10040000 0xc 0xffff0000>;
			interrupts = <0x0 0x55 0x8 0x0 0x56 0x8>;
			isp_frame_done_p2_0 = <0x43>;
			isp_frame_done_p2_1 = <0x42>;
			kp_base = <0x10010000 0x9 0xffff0000>;
			mcucfg_base = <0x10200000 0xe 0xffff0000>;
			mdp_rdma0_frame_done = <0x12>;
			mdp_rdma0_sof = <0x0>;
			mdp_rsz0_frame_done = <0x13>;
			mdp_rsz0_sof = <0x1>;
			mdp_rsz1_frame_done = <0x14>;
			mdp_rsz1_sof = <0x2>;
			mdp_tdshp_frame_done = <0x15>;
			mdp_tdshp_sof = <0x3>;
			mdp_wdma_frame_done = <0x16>;
			mdp_wdma_sof = <0x4>;
			mdp_wrot_read_frame_done = <0x18>;
			mdp_wrot_sof = <0x5>;
			mdp_wrot_write_frame_done = <0x17>;
			mm_na_base = <0x14020000 0x3 0xffff0000>;
			mmsys_config_base = <0x14000000 0x1 0xffff0000>;
			msdc0_base = <0x11230000 0x13 0xffff0000>;
			msdc1_base = <0x11240000 0x14 0xffff0000>;
			msdc2_base = <0x11250000 0x15 0xffff0000>;
			msdc3_base = <0x11260000 0x16 0xffff0000>;
			pwm_sw_base = <0x1100f000 0x63 0xfffff000>;
			reg = <0x1020a000 0x1000>;
			scp_base = <0x10050000 0xd 0xffff0000>;
			scp_sram_base = <0x10020000 0xa 0xffff0000>;
			seninf_cam0_fifo_full = <0x49>;
			stream_done_0 = <0x26>;
			stream_done_1 = <0x27>;
			stream_done_2 = <0x28>;
			stream_done_3 = <0x29>;
			stream_done_4 = <0x2a>;
			stream_done_5 = <0x2b>;
			stream_done_6 = <0x2c>;
			stream_done_7 = <0x2d>;
			stream_done_8 = <0x2e>;
			stream_done_9 = <0x2f>;
			topckgen_base = <0x10000000 0x8 0xffff0000>;
			usb0_base = <0x11200000 0x10 0xffff0000>;
			usb_sif_base = <0x11210000 0x11 0xffff0000>;
			vdec_gcon_base = <0x16000000 0x5 0xffff0000>;
			venc_gcon_base = <0x17000000 0x6 0xffff0000>;
		};

		glance_gesture@0 {
			compatible = "mediatek,glance_gesture";
		};

		gpio {
			GPIO_SIM1_SCLK = <0x16>;
			GPIO_SIM1_SIO = <0x17>;
			compatible = "mediatek,gpio_usage_mapping";
		};

		gpio@0x10005000 {
			compatible = "mediatek,gpio";
			reg = <0x10005000 0x1000>;
		};

		gps {
			compatible = "mediatek,gps";
		};

		gse_1 {
			compatible = "mediatek, gse_1-eint";
			status = "disabled";
		};

		gsensor@0 {
			compatible = "mediatek,gsensor";
		};

		gyroscope@0 {
			compatible = "mediatek,gyroscope";
			pinctrl-0 = <0x49>;
			pinctrl-1 = <0x4a>;
			pinctrl-names = "pin_default", "pin_cfg";
			status = "okay";
		};

		hacc@0x1000A000 {
			compatible = "mediatek,hacc";
			interrupts = <0x0 0x6e 0x0>;
			reg = <0x1000a000 0x1000>;
		};

		hall {
			compatible = "mediatek,mt6580-hall";
			debounce = <0x78 0x80>;
			interrupt-parent = <0xc>;
			interrupts = <0x78 0x2>;
		};

		heart_rate@0 {
			compatible = "mediatek,heart_rate";
		};

		hwmsensor@0 {
			compatible = "mediatek,hwmsensor";
		};

		i2c@11009000 {
			#address-cells = <0x1>;
			#size-cells = <0x0>;
			cell-index = <0x0>;
			clock-div = <0xa>;
			compatible = "mediatek,mt6580-i2c", "mediatek,i2c0";
			interrupts = <0x0 0x28 0x8 0x0 0x32 0x8>;
			reg = <0x11009000 0x1000>;

			camera_main@7a {
				compatible = "mediatek,camera_main";
				reg = <0x7a>;
				status = "okay";
			};

			camera_main_af@28 {
				compatible = "mediatek,camera_main_af";
				reg = <0x28>;
				status = "okay";
			};

			camera_sub@78 {
				compatible = "mediatek,camera_sub";
				reg = <0x78>;
				status = "okay";
			};
		};

		i2c@1100a000 {
			#address-cells = <0x1>;
			#size-cells = <0x0>;
			cell-index = <0x1>;
			clock-div = <0xa>;
			compatible = "mediatek,mt6580-i2c", "mediatek,i2c1";
			interrupts = <0x0 0x29 0x8 0x0 0x33 0x8>;
			reg = <0x1100a000 0x1000>;

			cap_touch@5d {
				compatible = "mediatek,cap_touch";
				reg = <0x5d>;
				status = "okay";
			};

			ext_buck@60 {
				compatible = "mediatek,ext_buck";
				reg = <0x60>;
				status = "okay";
			};

			fan5405@6a {
				compatible = "fan5405";
				reg = <0x6a>;
				status = "okay";
			};
		};

		i2c@1100b000 {
			#address-cells = <0x1>;
			#size-cells = <0x0>;
			cell-index = <0x2>;
			clock-div = <0xa>;
			compatible = "mediatek,mt6580-i2c", "mediatek,i2c2";
			interrupts = <0x0 0x2a 0x8 0x0 0x34 0x8>;
			reg = <0x1100b000 0x1000>;

			alsps@60 {
				compatible = "mediatek,alsps";
				reg = <0x60>;
				status = "okay";
			};

			gsensor@18 {
				compatible = "mediatek,gsensor";
				reg = <0x18>;
				status = "okay";
			};

			gyro@68 {
				compatible = "mediatek,gyro";
				reg = <0x68>;
				status = "okay";
			};

			msensor@0d {
				compatible = "mediatek,msensor";
				reg = <0xd>;
				status = "okay";
			};

			strobe_main@63 {
				compatible = "mediatek,strobe_main";
				reg = <0x63>;
				status = "okay";
			};
		};

		in_pocket@0 {
			compatible = "mediatek,in_pocket";
		};

		kd_camera_hw1@15008000 {
			compatible = "mediatek,camera_hw";
			pinctrl-0 = <0x36>;
			pinctrl-1 = <0x37>;
			pinctrl-10 = <0x40>;
			pinctrl-11 = <0x41>;
			pinctrl-12 = <0x42>;
			pinctrl-13 = <0x43>;
			pinctrl-14 = <0x44>;
			pinctrl-15 = <0x45>;
			pinctrl-16 = <0x46>;
			pinctrl-2 = <0x38>;
			pinctrl-3 = <0x39>;
			pinctrl-4 = <0x3a>;
			pinctrl-5 = <0x3b>;
			pinctrl-6 = <0x3c>;
			pinctrl-7 = <0x3d>;
			pinctrl-8 = <0x3e>;
			pinctrl-9 = <0x3f>;
			pinctrl-names = "default", "cam0_rst0", "cam0_rst1", "cam0_pnd0", "cam0_pnd1", "cam1_rst0", "cam1_rst1", "cam1_pnd0", "cam1_pnd1", "cam_ldo0_0", "cam_ldo0_1", "cam1_gpio_serial", "cam1_gpio_mipi", "cam_mclk1_enable", "cam_mclk1_disable", "cam_mclk2_enable", "cam_mclk2_disable";
			reg = <0x15008000 0x1000>;
			status = "okay";
			vcama-supply = <0x32>;
			vcama_main2-supply = <0x32>;
			vcama_sub-supply = <0x32>;
			vcamaf-supply = <0x34>;
			vcamd-supply = <0x33>;
			vcamd_main2-supply = <0x33>;
			vcamd_sub-supply = <0x33>;
			vcamio-supply = <0x35>;
			vcamio_main2-supply = <0x35>;
			vcamio_sub-supply = <0x35>;
		};

		kd_camera_hw2@15008000 {
			compatible = "mediatek,camera_hw2";
			reg = <0x15008000 0x1000>;
		};

		keypad@10002000 {
			compatible = "mediatek,mt6580-keypad";
			interrupts = <0x0 0x6d 0x2>;
			mediatek,kpd-hw-dl-key1 = <0x0>;
			mediatek,kpd-hw-dl-key2 = <0x11>;
			mediatek,kpd-hw-dl-key3 = <0x8>;
			mediatek,kpd-hw-factory-key = <0x11>;
			mediatek,kpd-hw-init-map = <0x73 0x0 0x0 0x0 0x0 0x0 0x0 0x0 0x0 0x0 0x0 0x0 0x0 0x0 0x0 0x0 0x0 0x0 0x0 0x0 0x0 0x0 0x0 0x0 0x0 0x0 0x0 0x0 0x0 0x0 0x0 0x0 0x0 0x0 0x0 0x0 0x0 0x0 0x0 0x0 0x0 0x0 0x0 0x0 0x0 0x0 0x0 0x0 0x0 0x0 0x0 0x0 0x0 0x0 0x0 0x0 0x0 0x0 0x0 0x0 0x0 0x0 0x0 0x0 0x0 0x0 0x0 0x0 0x0 0x0 0x0 0x0>;
			mediatek,kpd-hw-map-num = <0x48>;
			mediatek,kpd-hw-pwrkey = <0x8>;
			mediatek,kpd-hw-recovery-key = <0x0>;
			mediatek,kpd-hw-rstkey = <0x11>;
			mediatek,kpd-key-debounce = <0x400>;
			mediatek,kpd-pwkey-gpio-din = <0x0>;
			mediatek,kpd-pwrkey-eint-gpio = <0x0>;
			mediatek,kpd-sw-pwrkey = <0x74>;
			mediatek,kpd-sw-rstkey = <0x72>;
			mediatek,kpd-use-extend-type = <0x0>;
			reg = <0x10002000 0x1000>;
			status = "okay";
		};

		lcm {
			compatible = "mediatek,mt6580-lcm";
			gpio_lcm_bl = <0x4 0xc 0x0>;
			gpio_lcm_pwr = <0x4 0xb 0x0>;
			gpio_lcm_rst = <0x4 0x46 0x0>;
		};

		m4u@10203000 {
			cell-index = <0x0>;
			compatible = "mediatek,m4u";
			interrupts = <0x0 0x51 0x8>;
			reg = <0x10203000 0x1000>;
		};

		m_acc_pl@0 {
			compatible = "mediatek,m_acc_pl";
		};

		m_act_pl@0 {
			compatible = "mediatek,m_act_pl";
		};

		m_alsps_pl@0 {
			compatible = "mediatek,m_alsps_pl";
		};

		m_baro_pl@0 {
			compatible = "mediatek,m_baro_pl";
		};

		m_batch_pl@0 {
			compatible = "mediatek,m_batch_pl";
		};

		m_fdn_pl@0 {
			compatible = "mediatek,m_fdn_pl";
		};

		m_glg_pl@0 {
			compatible = "mediatek,m_glg_pl";
		};

		m_gyro_pl@0 {
			compatible = "mediatek,m_gyro_pl";
		};

		m_hrm_pl@0 {
			compatible = "mediatek,m_hrm_pl";
		};

		m_inpk_pl@0 {
			compatible = "mediatek,m_inpk_pl";
		};

		m_mag_pl@0 {
			compatible = "mediatek,m_mag_pl";
		};

		m_pdr_pl@0 {
			compatible = "mediatek,m_pdr_pl";
		};

		m_pkup_pl@0 {
			compatible = "mediatek,m_pkup_pl";
		};

		m_shk_pl@0 {
			compatible = "mediatek,m_shk_pl";
		};

		m_step_c_pl@0 {
			compatible = "mediatek,m_step_c_pl";
		};

		m_tilt_pl@0 {
			compatible = "mediatek,m_tilt_pl";
		};

		m_wag_pl@0 {
			compatible = "mediatek,m_wag_pl";
		};

		mcucfg@10200000 {
			compatible = "mediatek,mt6580-mcucfg";
			reg = <0x10200000 0x200>;
		};

		mdp_rdma@14001000 {
			compatible = "mediatek,mdp_rdma";
			interrupts = <0x0 0x71 0x8>;
			reg = <0x14001000 0x1000>;
		};

		mdp_rsz0@14002000 {
			compatible = "mediatek,mdp_rsz0";
			interrupts = <0x0 0x72 0x8>;
			reg = <0x14002000 0x1000>;
		};

		mdp_rsz1@14003000 {
			compatible = "mediatek,mdp_rsz1";
			interrupts = <0x0 0x73 0x8>;
			reg = <0x14003000 0x1000>;
		};

		mdp_tdshp@14006000 {
			compatible = "mediatek,mdp_tdshp";
			interrupts = <0x0 0x74 0x8>;
			reg = <0x14006000 0x1000>;
		};

		mdp_wdma@14004000 {
			compatible = "mediatek,mdp_wdma";
			interrupts = <0x0 0x75 0x8>;
			reg = <0x14004000 0x1000>;
		};

		mdp_wrot@14005000 {
			compatible = "mediatek,mdp_wrot";
			interrupts = <0x0 0x76 0x8>;
			reg = <0x14005000 0x1000>;
		};

		mmsys_config@14000000 {
			compatible = "mediatek,mmsys_config";
			interrupts = <0x0 0x84 0x8>;
			reg = <0x14000000 0x1000>;
		};

		msensor@0 {
			compatible = "mediatek,msensor";
		};

		mt_soc_codec_dummy_name@11140000 {
			compatible = "mediatek,mt_soc_codec_dummy";
		};

		mt_soc_codec_name@11140000 {
			compatible = "mediatek,mt_soc_codec_63xx";
		};

		mt_soc_dai_name@11140000 {
			compatible = "mediatek,mt_soc_dai_stub";
		};

		mt_soc_dl1_awb_pcm@11140000 {
			compatible = "mediatek,mt_soc_pcm_dl1_awb";
		};

		mt_soc_dl1_pcm@11140000 {
			audclk-gpio = <0x1a 0x0>;
			audmiso-gpio = <0x1c 0x0>;
			audmosi-gpio = <0x1b 0x0>;
			compatible = "mediatek,mt_soc_pcm_dl1";
			interrupts = <0x0 0x50 0x8>;
			pinctrl-0 = <0x27>;
			pinctrl-1 = <0x28>;
			pinctrl-2 = <0x29>;
			pinctrl-3 = <0x2a>;
			pinctrl-4 = <0x2b>;
			pinctrl-5 = <0x2c>;
			pinctrl-6 = <0x2d>;
			pinctrl-names = "default", "audpmicclk-mode0", "audpmicclk-mode1", "spksd-pullhigh", "pksd-pulllow", "ausw-pullhigh", "ausw-pulllow";
			reg = <0x11140000 0x1000>;
			status = "okay";
		};

		mt_soc_dl2_pcm@11140000 {
			compatible = "mediatek,mt_soc_pcm_dl2";
		};

		mt_soc_dummy_pcm@11140000 {
			compatible = "mediatek,mt_soc_pcm_dummy";
		};

		mt_soc_fm_i2s_awb_pcm@11140000 {
			compatible = "mediatek,mt_soc_pcm_fm_i2s_awb";
		};

		mt_soc_fm_i2s_pcm@0x11140000 {
			compatible = "mediatek,mt_soc_pcm_fm_i2s";
		};

		mt_soc_fm_mrgtx_pcm@11140000 {
			compatible = "mediatek,mt_soc_pcm_fmtx";
		};

		mt_soc_hdmi_pcm@11140000 {
			compatible = "mediatek,mt_soc_pcm_hdmi";
		};

		mt_soc_hp_impedance_pcm@11140000 {
			compatible = "mediatek,Mt_soc_pcm_hp_impedance";
		};

		mt_soc_i2s0_awb_pcm@11140000 {
			compatible = "mediatek,mt_soc_pcm_i2s0_awb";
		};

		mt_soc_i2s0_pcm@11140000 {
			compatible = "mediatek,mt_soc_pcm_dl1_i2s0";
		};

		mt_soc_i2s0dl1_pcm@11140000 {
			compatible = "mediatek,mt_soc_pcm_dl1_i2s0Dl1";
		};

		mt_soc_mrgrx_awb_pcm@11140000 {
			compatible = "mediatek,mt_soc_pcm_mrgrx_awb";
		};

		mt_soc_mrgrx_pcm@11140000 {
			compatible = "mediatek,mt_soc_pcm_mrgrx";
		};

		mt_soc_routing_dai_name@11140000 {
			compatible = "mediatek,mt_soc_dai_routing";
		};

		mt_soc_routing_pcm@11140000 {
			compatible = "mediatek,mt_soc_pcm_routing";
		};

		mt_soc_tdmrx_pcm@11140000 {
			compatible = "mediatek,mt_soc_tdm_capture";
		};

		mt_soc_ul1_PCM@11140000 {
			compatible = "mediatek,mt_soc_pcm_capture";
		};

		mt_soc_ul2_pcm@11140000 {
			compatible = "mediatek,mt_soc_pcm_capture2";
		};

		mt_soc_uldlloopback_pcm@11140000 {
			compatible = "mediatek,mt_soc_pcm_uldlloopback";
		};

		mt_soc_voice_md1@11140000 {
			compatible = "mediatek,mt_soc_pcm_voice_md1";
		};

		mt_soc_voice_md1_bt@11140000 {
			compatible = "mediatek,mt_soc_pcm_voice_md1_bt";
		};

		mt_soc_voice_md2@11140000 {
			compatible = "mediatek,mt_soc_pcm_voice_md2";
		};

		mt_soc_voice_md2_bt@11140000 {
			compatible = "mediatek,mt_soc_pcm_voice_md2_bt";
		};

		mt_soc_voip_bt_in@11140000 {
			compatible = "mediatek,mt_soc_pcm_bt_dai";
		};

		mt_soc_voip_bt_out@11140000 {
			compatible = "mediatek,mt_soc_pcm_dl1_bt";
		};

		mtkfb@0 {
			compatible = "mediatek,mtkfb";
			pinctrl-0 = <0x1b>;
			pinctrl-1 = <0x4b>;
			pinctrl-2 = <0x4c>;
			pinctrl-3 = <0x4d>;
			pinctrl-4 = <0x4e>;
			pinctrl-5 = <0x4f>;
			pinctrl-names = "default", "mode_te_gpio", "mode_te_te", "lcm_rst_out0_gpio", "lcm_rst_out1_gpio", "pwm_test_pin_mux_gpio66";
			status = "okay";
		};

		nfc {
			compatible = "mediatek,nfc-gpio-v2";
			gpio-eint = <0xc>;
			gpio-irq = <0x9>;
			gpio-rst = <0xa>;
			gpio-ven = <0xb>;
		};

		orientation@0 {
			compatible = "mediatek,orientation";
		};

		pedometer@0 {
			compatible = "mediatek,pedometer";
		};

		pick_up@0 {
			compatible = "mediatek,pick_up";
		};

		pinctrl@0x10005000 {
			#gpio-cells = <0x2>;
			compatible = "mediatek,mt6580-pinctrl";
			gpio-controller;
			linux,phandle = <0x4>;
			mediatek,pctl-regmap = <0xd>;
			phandle = <0x4>;
			pins-are-numbered;
			reg = <0x10005000 0x1000>;

			alspsdefaultcfg {
				linux,phandle = <0x47>;
				phandle = <0x47>;
			};

			alspspincfg {
				linux,phandle = <0x48>;
				phandle = <0x48>;

				pins_cmd_dat {
					bias-pull-up = <0x0>;
					pins = <0x600>;
					slew-rate = <0x0>;
				};
			};

			audiodefault {
				linux,phandle = <0x27>;
				phandle = <0x27>;
			};

			auswhigh {
				linux,phandle = <0x2c>;
				phandle = <0x2c>;

				pins_cmd_dat {
					output-high;
					pins = <0x1500>;
					slew-rate = <0x1>;
				};
			};

			auswlow {
				linux,phandle = <0x2d>;
				phandle = <0x2d>;

				pins_cmd_dat {
					output-low;
					pins = <0x1500>;
					slew-rate = <0x1>;
				};
			};

			cam0@0 {
				linux,phandle = <0x37>;
				phandle = <0x37>;

				pins_cmd_dat {
					output-low;
					pins = <0x4900>;
					slew-rate = <0x1>;
				};
			};

			cam0@1 {
				linux,phandle = <0x38>;
				phandle = <0x38>;

				pins_cmd_dat {
					output-high;
					pins = <0x4900>;
					slew-rate = <0x1>;
				};
			};

			cam0@2 {
				linux,phandle = <0x39>;
				phandle = <0x39>;

				pins_cmd_dat {
					output-low;
					pins = <0x4700>;
					slew-rate = <0x1>;
				};
			};

			cam0@3 {
				linux,phandle = <0x3a>;
				phandle = <0x3a>;

				pins_cmd_dat {
					output-high;
					pins = <0x4700>;
					slew-rate = <0x1>;
				};
			};

			cam1@0 {
				linux,phandle = <0x3b>;
				phandle = <0x3b>;

				pins_cmd_dat {
					output-low;
					pins = <0x4c00>;
					slew-rate = <0x1>;
				};
			};

			cam1@1 {
				linux,phandle = <0x3c>;
				phandle = <0x3c>;

				pins_cmd_dat {
					output-high;
					pins = <0x4c00>;
					slew-rate = <0x1>;
				};
			};

			cam1@2 {
				linux,phandle = <0x3d>;
				phandle = <0x3d>;

				pins_cmd_dat {
					output-low;
					pins = <0x4a00>;
					slew-rate = <0x1>;
				};
			};

			cam1@3 {
				linux,phandle = <0x3e>;
				phandle = <0x3e>;

				pins_cmd_dat {
					output-high;
					pins = <0x4a00>;
					slew-rate = <0x1>;
				};
			};

			cam1mipi@0 {
				linux,phandle = <0x42>;
				phandle = <0x42>;

				pins_cmd_dat {
					pins = <0x2301>;
				};

				pins_cmd_dat1 {
					pins = <0x2401>;
				};

				pins_cmd_dat2 {
					pins = <0x2501>;
				};

				pins_cmd_dat3 {
					pins = <0x2601>;
				};

				pins_cmd_dat4 {
					pins = <0x2701>;
				};

				pins_cmd_dat5 {
					pins = <0x2801>;
				};
			};

			cam1serial@0 {
				linux,phandle = <0x41>;
				phandle = <0x41>;

				pins_cmd_dat {
					pins = <0x2302>;
				};

				pins_cmd_dat1 {
					pins = <0x2402>;
				};

				pins_cmd_dat2 {
					pins = <0x2502>;
				};

				pins_cmd_dat3 {
					pins = <0x2602>;
				};

				pins_cmd_dat4 {
					pins = <0x2702>;
				};
			};

			cam@0 {
				linux,phandle = <0x3f>;
				phandle = <0x3f>;
			};

			cam@1 {
				linux,phandle = <0x40>;
				phandle = <0x40>;
			};

			camdefault {
				linux,phandle = <0x36>;
				phandle = <0x36>;
			};

			default {
				linux,phandle = <0x1b>;
				phandle = <0x1b>;
			};

			drvvbus_high {
				linux,phandle = <0x23>;
				phandle = <0x23>;

				pins_cmd_dat {
					output-high;
					pins = <0x1900>;
					slew-rate = <0x1>;
				};
			};

			drvvbus_init {
				linux,phandle = <0x21>;
				phandle = <0x21>;

				pins_cmd_dat {
					bias-pull-up = <0x0>;
					pins = <0x1900>;
					slew-rate = <0x1>;
				};
			};

			drvvbus_low {
				linux,phandle = <0x22>;
				phandle = <0x22>;

				pins_cmd_dat {
					output-low;
					pins = <0x1900>;
					slew-rate = <0x1>;
				};
			};

			eint0default {
				linux,phandle = <0x15>;
				phandle = <0x15>;
			};

			eint@0 {
				linux,phandle = <0x16>;
				phandle = <0x16>;

				pins_cmd_dat {
					bias-disable;
					pins = <0x406>;
					slew-rate = <0x0>;
				};
			};

			eintoutput0 {
				linux,phandle = <0x11>;
				phandle = <0x11>;

				pins_cmd_dat {
					output-low;
					pins = <0x500>;
					slew-rate = <0x1>;
				};
			};

			eintoutput1 {
				linux,phandle = <0x12>;
				phandle = <0x12>;

				pins_cmd_dat {
					output-high;
					pins = <0x500>;
					slew-rate = <0x1>;
				};
			};

			enable_high {
				linux,phandle = <0x2e>;
				phandle = <0x2e>;

				pins_cmd_dat {
					output-high;
					pins = <0x1400>;
					slew-rate = <0x1>;
				};
			};

			enable_low {
				linux,phandle = <0x2f>;
				phandle = <0x2f>;

				pins_cmd_dat {
					output-low;
					pins = <0x1400>;
					slew-rate = <0x1>;
				};
			};

			gpslna@0 {
				linux,phandle = <0x1c>;
				phandle = <0x1c>;

				pins_cmd_dat {
					bias-disable;
					output-low;
					pins = <0x4300>;
					slew-rate = <0x0>;
				};
			};

			gpslna@1 {
				linux,phandle = <0x1d>;
				phandle = <0x1d>;

				pins_cmd_dat {
					output-high;
					pins = <0x4300>;
					slew-rate = <0x1>;
				};
			};

			gpslna@2 {
				linux,phandle = <0x1e>;
				phandle = <0x1e>;

				pins_cmd_dat {
					output-low;
					pins = <0x4300>;
					slew-rate = <0x1>;
				};
			};

			gyrodefaultcfg {
				linux,phandle = <0x49>;
				phandle = <0x49>;
			};

			gyropincfg {
				linux,phandle = <0x4a>;
				phandle = <0x4a>;

				pins_cmd_dat {
					bias-pull-down = <0x0>;
					pins = <0x100>;
					slew-rate = <0x0>;
				};
			};

			iddig_irq_init {
				linux,phandle = <0x20>;
				phandle = <0x20>;

				pins_cmd_dat {
					bias-pull-up = <0x0>;
					pins = <0x1006>;
					slew-rate = <0x0>;
				};
			};

			lcm_rst_out0_gpio {
				linux,phandle = <0x4d>;
				phandle = <0x4d>;

				pins_cmd_dat {
					output-low;
					pins = <0x4601>;
					slew-rate = <0x1>;
				};
			};

			lcm_rst_out1_gpio {
				linux,phandle = <0x4e>;
				phandle = <0x4e>;

				pins_cmd_dat {
					output-high;
					pins = <0x4601>;
					slew-rate = <0x1>;
				};
			};

			mclk1disable@0 {
				linux,phandle = <0x44>;
				phandle = <0x44>;

				pins_cmd_dat {
					pins = <0x4800>;
				};
			};

			mclk1enable@0 {
				linux,phandle = <0x43>;
				phandle = <0x43>;

				pins_cmd_dat {
					pins = <0x4801>;
				};
			};

			mclk2disable@0 {
				linux,phandle = <0x46>;
				phandle = <0x46>;

				pins_cmd_dat {
					pins = <0x4b00>;
				};
			};

			mclk2enable@0 {
				linux,phandle = <0x45>;
				phandle = <0x45>;

				pins_cmd_dat {
					pins = <0x4b01>;
				};
			};

			mmc0@default {
				linux,phandle = <0x2>;
				phandle = <0x2>;

				pins_clk {
					drive-strength = [02];
				};

				pins_cmd {
					drive-strength = [02];
				};

				pins_dat {
					drive-strength = [02];
				};

				pins_ds {
					drive-strength = [02];
				};

				pins_rst {
					drive-strength = [02];
				};
			};

			mmc0@register_default {
				cmd_edge = [01];
				cmdrddly = [00];
				cmdrrddly = [00];
				dat0rddly = [00];
				dat1rddly = [00];
				dat2rddly = [00];
				dat3rddly = [00];
				dat4rddly = [00];
				dat5rddly = [00];
				dat6rddly = [00];
				dat7rddly = [00];
				datwrddly = [00];
				ett-hs200-cells = <0xc>;
				ett-hs200-default = <0xb0 0x380 0x0 0xb0 0x7c00 0x0 0xb4 0x38 0x1 0x4 0x2 0x1 0xf0 0x1f0000 0x0 0xf0 0x7c00000 0x0 0xb4 0x7 0x1 0xf0 0x1f 0x0 0x4 0x100 0x1 0xf8 0x1f000000 0x0 0xf0 0x1f00 0x0 0xb0 0x8 0x1>;
				linux,phandle = <0x3>;
				phandle = <0x3>;
				rdata_edge = [01];
				wdata_edge = [01];
			};

			mmc1@ddr50 {
				linux,phandle = <0xa>;
				phandle = <0xa>;

				pins_clk {
					drive-strength = [03];
				};

				pins_cmd {
					drive-strength = [02];
				};

				pins_dat {
					drive-strength = [02];
				};
			};

			mmc1@default {
				linux,phandle = <0x7>;
				phandle = <0x7>;

				pins_clk {
					drive-strength = [03];
				};

				pins_cmd {
					drive-strength = [03];
				};

				pins_dat {
					drive-strength = [03];
				};
			};

			mmc1@register_default {
				cmd_edge = [01];
				cmdrddly = [00];
				cmdrrddly = [00];
				dat0rddly = [00];
				dat1rddly = [00];
				dat2rddly = [00];
				dat3rddly = [00];
				datwrddly = [00];
				linux,phandle = <0xb>;
				phandle = <0xb>;
				rdata_edge = [01];
				wdata_edge = [01];
			};

			mmc1@sdr104 {
				linux,phandle = <0x8>;
				phandle = <0x8>;

				pins_clk {
					drive-strength = [03];
				};

				pins_cmd {
					drive-strength = [02];
				};

				pins_dat {
					drive-strength = [02];
				};
			};

			mmc1@sdr50 {
				linux,phandle = <0x9>;
				phandle = <0x9>;

				pins_clk {
					drive-strength = [03];
				};

				pins_cmd {
					drive-strength = [02];
				};

				pins_dat {
					drive-strength = [02];
				};
			};

			mmc1_ins_cfg {
				linux,phandle = <0x6>;
				phandle = <0x6>;

				pins_insert {
					bias-pull-up = <0x0>;
					input-schmitt-enable = <0x1>;
					pins = <0x1106>;
					slew-rate = <0x0>;
				};
			};

			mmc1_ins_default {
				linux,phandle = <0x5>;
				phandle = <0x5>;
			};

			mode_high {
				linux,phandle = <0x30>;
				phandle = <0x30>;

				pins_cmd_dat {
					output-high;
					pins = <0x1400>;
					slew-rate = <0x1>;
				};
			};

			mode_low {
				linux,phandle = <0x31>;
				phandle = <0x31>;

				pins_cmd_dat {
					output-low;
					pins = <0x1400>;
					slew-rate = <0x1>;
				};
			};

			mode_te_gpio {
				linux,phandle = <0x4b>;
				phandle = <0x4b>;

				pins_cmd_dat {
					pins = <0x4400>;
				};
			};

			mode_te_te {
				linux,phandle = <0x4c>;
				phandle = <0x4c>;

				pins_cmd_dat {
					pins = <0x4401>;
				};
			};

			otgusben_high {
				linux,phandle = <0x26>;
				phandle = <0x26>;

				pins_cmd_dat {
					output-high;
					pins = <0x4400>;
					slew-rate = <0x1>;
				};
			};

			otgusben_low {
				linux,phandle = <0x25>;
				phandle = <0x25>;

				pins_cmd_dat {
					output-low;
					pins = <0x4400>;
					slew-rate = <0x1>;
				};
			};

			otgusden_init {
				linux,phandle = <0x24>;
				phandle = <0x24>;

				pins_cmd_dat {
					bias-pull-up = <0x0>;
					pins = <0x4400>;
					slew-rate = <0x1>;
				};
			};

			pmicclkmode0 {
				linux,phandle = <0x28>;
				phandle = <0x28>;

				pins_cmd0_dat {
					pins = <0x1a00>;
				};

				pins_cmd1_dat {
					pins = <0x1c00>;
				};

				pins_cmd2_dat {
					pins = <0x1b00>;
				};
			};

			pmicclkmode1 {
				linux,phandle = <0x29>;
				phandle = <0x29>;

				pins_cmd0_dat {
					pins = <0x1a01>;
				};

				pins_cmd1_dat {
					pins = <0x1c01>;
				};

				pins_cmd2_dat {
					pins = <0x1b01>;
				};
			};

			pwm_test_pin_mux_gpio66 {
				linux,phandle = <0x4f>;
				phandle = <0x4f>;

				pins_cmd_dat {
					pins = <0x4201>;
					slew-rate = <0x1>;
				};
			};

			rstoutput0 {
				linux,phandle = <0x13>;
				phandle = <0x13>;

				pins_cmd_dat {
					output-low;
					pins = <0x1200>;
					slew-rate = <0x1>;
				};
			};

			rstoutput1 {
				linux,phandle = <0x14>;
				phandle = <0x14>;

				pins_cmd_dat {
					output-high;
					pins = <0x1200>;
					slew-rate = <0x1>;
				};
			};

			spksdhigh {
				linux,phandle = <0x2a>;
				phandle = <0x2a>;

				pins_cmd_dat {
					output-high;
					pins = <0x1800>;
					slew-rate = <0x1>;
				};
			};

			spksdlow {
				linux,phandle = <0x2b>;
				phandle = <0x2b>;

				pins_cmd_dat {
					output-low;
					pins = <0x1800>;
					slew-rate = <0x1>;
				};
			};

			toucheint5default {
				linux,phandle = <0xf>;
				phandle = <0xf>;
			};

			toucheint@5 {
				linux,phandle = <0x10>;
				phandle = <0x10>;

				pins_cmd_dat {
					bias-disable;
					pins = <0x506>;
					slew-rate = <0x0>;
				};
			};

			usb_default {
				linux,phandle = <0x1f>;
				phandle = <0x1f>;
			};
		};

		seninf_top@15008000 {
			compatible = "mediatek,SENINF_TOP";
			interrupts = <0x0 0x8e 0x8>;
			reg = <0x15008000 0x1000>;
		};

		sensorHub@0 {
			compatible = "mediatek,sensorHub";
		};

		shake@0 {
			compatible = "mediatek,shake";
		};

		shf@0 {
			compatible = "mediatek,shf";
		};

		spi@1100c000 {
			cell-index = <0x0>;
			compatible = "mediatek,mt6580-spi";
			interrupts = <0x0 0x40 0x8>;
			mediatek,spi-padmacro = <0x0>;
			reg = <0x1100c000 0x1000>;
		};

		step_counter@0 {
			compatible = "mediatek,step_counter";
		};

		sys_cirq@10202000 {
			compatible = "mediatek,mt6580-sys_cirq", "mediatek,mt6735-sys_cirq";
			interrupts = <0x0 0x9e 0x8>;
			mediatek,cirq_num = <0x7e>;
			mediatek,spi_start_offset = <0x20>;
			reg = <0x10202000 0x1000>;
		};

		syscfg_pctl_a@0x10005000 {
			compatible = "mediatek,mt6580-pctl-a-syscfg", "syscon";
			linux,phandle = <0xd>;
			phandle = <0xd>;
			reg = <0x10211000 0x1000>;
		};

		tilt_detector@0 {
			compatible = "mediatek,tilt_detector";
		};

		touch@0 {
			compatible = "mediatek,mt6580-touch";
			debounce = <0x5 0x0>;
			interrupt-parent = <0xc>;
			interrupts = <0x5 0x2>;
			pinctrl-0 = <0xf>;
			pinctrl-1 = <0x10>;
			pinctrl-2 = <0x11>;
			pinctrl-3 = <0x12>;
			pinctrl-4 = <0x13>;
			pinctrl-5 = <0x14>;
			pinctrl-names = "default", "state_eint_as_int", "state_eint_output0", "state_eint_output1", "state_rst_output0", "state_rst_output1";
			status = "okay";
			tpd-filter-custom-prameters = <0x0 0x0 0x0 0x0 0x0 0x0 0x0 0x0 0x0 0x0 0x0 0x0>;
			tpd-filter-custom-speed = <0x0 0x0 0x0>;
			tpd-filter-enable = <0x1>;
			tpd-filter-pixel-density = <0x5d>;
			tpd-key-dim-local = <0x5a 0x373 0x64 0x28 0xe6 0x373 0x64 0x28 0x172 0x373 0x64 0x28 0x0 0x0 0x0 0x0>;
			tpd-key-local = <0x8b 0xac 0x9e 0x0>;
			tpd-key-num = <0x3>;
			tpd-max-touch-num = <0x5>;
			tpd-resolution = <0x258 0x400>;
			use-tpd-button = <0x0>;
			vtouch-supply = <0xe>;
		};

		usbphy@0 {
			compatible = "usb-nop-xceiv";
		};

		wake_gesture@0 {
			compatible = "mediatek,wake_gesture";
		};
	};

	chosen {
		atag,videolfb-fb_base = <0x9e800000>;
		atag,videolfb-fps = <0x1770>;
		atag,videolfb-islcmfound = <0x1>;
		atag,videolfb-lcmname = "nt35590_AUO";
		atag,videolfb-vramSize = <0x1800000>;
		bootargs = "console=tty0 console=ttyMT0,921600n1 root=/dev/ram initrd=0x84000000,0x400000 loglevel=8";
	};

	cpus {
		#address-cells = <0x1>;
		#size-cells = <0x0>;
		enable-method = "mediatek,mt6580-smp";

		cpu@0 {
			clock-frequency = <0x6553f100>;
			compatible = "arm,cortex-a7";
			device_type = "cpu";
			reg = <0x0>;
		};

		cpu@1 {
			clock-frequency = <0x6553f100>;
			compatible = "arm,cortex-a7";
			device_type = "cpu";
			reg = <0x1>;
		};

		cpu@2 {
			clock-frequency = <0x6553f100>;
			compatible = "arm,cortex-a7";
			device_type = "cpu";
			reg = <0x2>;
		};

		cpu@3 {
			clock-frequency = <0x6553f100>;
			compatible = "arm,cortex-a7";
			device_type = "cpu";
			reg = <0x3>;
		};
	};

	cust_accel@0 {
		compatible = "mediatek,bma222e_new";
		direction = <0x6>;
		firlen = <0x10>;
		i2c_addr = <0x18 0x0 0x0 0x0>;
		i2c_num = <0x2>;
		is_batch_supported = <0x0>;
		power_id = <0xffff>;
		power_vol = <0x0>;
	};

	cust_accel@1 {
		compatible = "mediatek,mir3da";
		direction = <0x7>;
		firlen = <0x10>;
		i2c_addr = <0x26 0x0 0x0 0x0>;
		i2c_num = <0x2>;
		is_batch_supported = <0x0>;
		power_id = <0xffff>;
		power_vol = <0x0>;
	};

	cust_accel@2 {
		compatible = "mediatek,mc3236";
		direction = <0x4>;
		firlen = <0x10>;
		i2c_addr = <0x4c 0x0 0x0 0x0>;
		i2c_num = <0x2>;
		is_batch_supported = <0x0>;
		power_id = <0xffff>;
		power_vol = <0x0>;
	};

	cust_alsps@0 {
		als_level = <0x5 0x9 0x24 0x3b 0x52 0x84 0xcd 0x111 0x1f4 0x34d 0x470 0x609 0x93c 0x122f 0x1b46>;
		als_value = <0x5a 0x78 0x91 0xe1 0x12c 0x226 0x3a2 0x4e2 0x6a4 0xa28 0x1400 0x1e00 0x2800 0x3c00 0x4f88 0x6310>;
		compatible = "mediatek,stk3x1x";
		i2c_addr = <0x90 0x0 0x0 0x0>;
		i2c_num = <0x2>;
		is_batch_supported_als = <0x0>;
		is_batch_supported_ps = <0x0>;
		polling_mode_als = <0x1>;
		polling_mode_ps = <0x1>;
		power_id = <0xffff>;
		power_vol = <0x0>;
		ps_threshold_high = <0x6a4>;
		ps_threshold_low = <0x5dc>;
	};

	cust_alsps@1 {
		als_level = <0x5 0x9 0x24 0x3b 0x52 0x84 0xcd 0x111 0x1f4 0x34d 0x470 0x609 0x93c 0x122f 0x1b46>;
		als_value = <0x5a 0x78 0x91 0xe1 0x12c 0x226 0x3a2 0x4e2 0x6a4 0xa28 0x1400 0x1e00 0x2800 0x3c00 0x4f88 0x6310>;
		compatible = "mediatek,ltr559";
		i2c_addr = <0x23 0x0 0x0 0x0>;
		i2c_num = <0x2>;
		is_batch_supported_als = <0x0>;
		is_batch_supported_ps = <0x0>;
		polling_mode_als = <0x1>;
		polling_mode_ps = <0x1>;
		power_id = <0xffff>;
		power_vol = <0x0>;
		ps_threshold_high = <0xfa>;
		ps_threshold_low = <0xc8>;
	};

	cust_mag@0 {
		compatible = "mediatek,s62x";
		direction = <0x2>;
		i2c_addr = <0xe 0x0 0x0 0x0>;
		i2c_num = <0x2>;
		is_batch_supported = <0x0>;
		power_id = <0xffff>;
		power_vol = <0x0>;
	};

	interrupt-controller@10210000 {
		#address-cells = <0x0>;
		#interrupt-cells = <0x3>;
		compatible = "arm,cortex-a7-gic";
		interrupt-controller;
		interrupts = <0x1 0x9 0xf04>;
		linux,phandle = <0x1>;
		phandle = <0x1>;
		reg = <0x0 0x10211000 0x0 0x1000 0x0 0x10212000 0x0 0x1000 0x0 0x10200100 0x0 0x1000>;
	};

	led@0 {
		compatible = "mediatek,red";
		data = <0x1>;
		led_mode = <0x0>;
		pwm_config = <0x0 0x0 0x0 0x0 0x0>;
	};

	led@1 {
		compatible = "mediatek,green";
		data = <0x1>;
		led_mode = <0x0>;
		pwm_config = <0x0 0x0 0x0 0x0 0x0>;
	};

	led@2 {
		compatible = "mediatek,blue";
		data = <0x1>;
		led_mode = <0x0>;
		pwm_config = <0x0 0x0 0x0 0x0 0x0>;
	};

	led@3 {
		compatible = "mediatek,jogball-backlight";
		data = <0x1>;
		led_mode = <0x0>;
		pwm_config = <0x0 0x0 0x0 0x0 0x0>;
	};

	led@4 {
		compatible = "mediatek,keyboard-backlight";
		data = <0x1>;
		led_mode = <0x0>;
		pwm_config = <0x0 0x0 0x0 0x0 0x0>;
	};

	led@5 {
		compatible = "mediatek,button-backlight";
		data = <0x1>;
		led_mode = <0x0>;
		pwm_config = <0x0 0x0 0x0 0x0 0x0>;
	};

	led@6 {
		compatible = "mediatek,lcd-backlight";
		data = <0x1>;
		led_mode = <0x5>;
		pwm_config = <0x0 0x0 0x0 0x0 0x0>;
	};

	memory@80000000 {
		device_type = "memory";
		reg = <0x0 0x80000000 0x0 0x1e800000>;
	};

	mt_pmic_regulator {
		compatible = "mediatek,mt_pmic";

		buck_regulators {
			compatible = "mediatek,mt_pmic_buck_regulators";

			buck_vpa {
				regulator-enable-ramp-delay = <0xb4>;
				regulator-max-microvolt = <0x37b1d0>;
				regulator-min-microvolt = <0x7a120>;
				regulator-name = "vpa";
				regulator-ramp-delay = <0xc350>;
			};

			buck_vproc {
				regulator-always-on;
				regulator-boot-on;
				regulator-enable-ramp-delay = <0xb4>;
				regulator-max-microvolt = <0x16caf6>;
				regulator-min-microvolt = <0xaae60>;
				regulator-name = "vproc";
				regulator-ramp-delay = <0x186a>;
			};
		};

		ldo_regulators {
			compatible = "mediatek,mt_pmic_ldo_regulators";

			ldo_va {
				linux,phandle = <0x51>;
				phandle = <0x51>;
				regulator-enable-ramp-delay = <0x6e>;
				regulator-max-microvolt = <0x2625a0>;
				regulator-min-microvolt = <0x1b7740>;
				regulator-name = "va";
			};

			ldo_vcama {
				linux,phandle = <0x32>;
				phandle = <0x32>;
				regulator-default-on = <0x0>;
				regulator-enable-ramp-delay = <0x108>;
				regulator-max-microvolt = <0x2ab980>;
				regulator-min-microvolt = <0x16e360>;
				regulator-name = "vcama";
				status = "okay";
			};

			ldo_vcamaf {
				linux,phandle = <0x34>;
				phandle = <0x34>;
				regulator-default-on = <0x0>;
				regulator-enable-ramp-delay = <0x108>;
				regulator-max-microvolt = <0x325aa0>;
				regulator-min-microvolt = <0x124f80>;
				regulator-name = "vcamaf";
				status = "okay";
			};

			ldo_vcamd {
				linux,phandle = <0x33>;
				phandle = <0x33>;
				regulator-default-on = <0x0>;
				regulator-enable-ramp-delay = <0x108>;
				regulator-max-microvolt = <0x1b7740>;
				regulator-min-microvolt = <0x124f80>;
				regulator-name = "vcamd";
				status = "okay";
			};

			ldo_vcamio {
				linux,phandle = <0x5f>;
				phandle = <0x5f>;
				regulator-enable-ramp-delay = <0xdc>;
				regulator-max-microvolt = <0x1b7740>;
				regulator-min-microvolt = <0x1b7740>;
				regulator-name = "vcamio";
			};

			ldo_vcn28 {
				linux,phandle = <0x18>;
				phandle = <0x18>;
				regulator-default-on = <0x0>;
				regulator-enable-ramp-delay = <0x108>;
				regulator-max-microvolt = <0x2ab980>;
				regulator-min-microvolt = <0x1b7740>;
				regulator-name = "vcn28";
				status = "okay";
			};

			ldo_vcn33_bt {
				linux,phandle = <0x19>;
				phandle = <0x19>;
				regulator-enable-ramp-delay = <0x108>;
				regulator-max-microvolt = <0x36ee80>;
				regulator-min-microvolt = <0x325aa0>;
				regulator-name = "vcn33_bt";
			};

			ldo_vcn33_wifi {
				linux,phandle = <0x1a>;
				phandle = <0x1a>;
				regulator-enable-ramp-delay = <0x108>;
				regulator-max-microvolt = <0x36ee80>;
				regulator-min-microvolt = <0x325aa0>;
				regulator-name = "vcn33_wifi";
			};

			ldo_vcn_1v8 {
				linux,phandle = <0x17>;
				phandle = <0x17>;
				regulator-default-on = <0x0>;
				regulator-enable-ramp-delay = <0x2c>;
				regulator-max-microvolt = <0x1b7740>;
				regulator-min-microvolt = <0x1b7740>;
				regulator-name = "vcn_1v8";
				status = "okay";
			};

			ldo_vemc_3v3 {
				linux,phandle = <0x57>;
				phandle = <0x57>;
				regulator-boot-on;
				regulator-default-on = <0x0>;
				regulator-enable-ramp-delay = <0x108>;
				regulator-max-microvolt = <0x325aa0>;
				regulator-min-microvolt = <0x2dc6c0>;
				regulator-name = "vemc_3v3";
				status = "okay";
			};

			ldo_vgp1 {
				linux,phandle = <0xe>;
				phandle = <0xe>;
				regulator-default-on = <0x0>;
				regulator-enable-ramp-delay = <0x108>;
				regulator-max-microvolt = <0x325aa0>;
				regulator-min-microvolt = <0x124f80>;
				regulator-name = "vgp1";
				status = "okay";
			};

			ldo_vgp2 {
				linux,phandle = <0x56>;
				phandle = <0x56>;
				regulator-default-on = <0x0>;
				regulator-enable-ramp-delay = <0x108>;
				regulator-max-microvolt = <0x2dc6c0>;
				regulator-min-microvolt = <0x124f80>;
				regulator-name = "vgp2";
				status = "okay";
			};

			ldo_vgp3 {
				linux,phandle = <0x60>;
				phandle = <0x60>;
				regulator-default-on = <0x0>;
				regulator-enable-ramp-delay = <0x108>;
				regulator-max-microvolt = <0x1b7740>;
				regulator-min-microvolt = <0x124f80>;
				regulator-name = "vgp3";
				status = "okay";
			};

			ldo_vibr {
				linux,phandle = <0x5a>;
				phandle = <0x5a>;
				regulator-default-on = <0x0>;
				regulator-enable-ramp-delay = <0x2c>;
				regulator-max-microvolt = <0x325aa0>;
				regulator-min-microvolt = <0x124f80>;
				regulator-name = "vibr";
				status = "okay";
			};

			ldo_vio18 {
				linux,phandle = <0x5e>;
				phandle = <0x5e>;
				regulator-boot-on;
				regulator-enable-ramp-delay = <0x108>;
				regulator-max-microvolt = <0x1b7740>;
				regulator-min-microvolt = <0x1b7740>;
				regulator-name = "vio18";
			};

			ldo_vio28 {
				linux,phandle = <0x52>;
				phandle = <0x52>;
				regulator-boot-on;
				regulator-enable-ramp-delay = <0x108>;
				regulator-max-microvolt = <0x2ab980>;
				regulator-min-microvolt = <0x2ab980>;
				regulator-name = "vio28";
			};

			ldo_vm {
				linux,phandle = <0x5c>;
				phandle = <0x5c>;
				regulator-boot-on;
				regulator-default-on = <0x0>;
				regulator-enable-ramp-delay = <0x108>;
				regulator-max-microvolt = <0x1b7740>;
				regulator-min-microvolt = <0x124f80>;
				regulator-name = "vm";
				status = "okay";
			};

			ldo_vmc {
				linux,phandle = <0x58>;
				phandle = <0x58>;
				regulator-default-on = <0x0>;
				regulator-enable-ramp-delay = <0x2c>;
				regulator-max-microvolt = <0x325aa0>;
				regulator-min-microvolt = <0x1b7740>;
				regulator-name = "vmc";
				status = "okay";
			};

			ldo_vmch {
				linux,phandle = <0x59>;
				phandle = <0x59>;
				regulator-default-on = <0x0>;
				regulator-enable-ramp-delay = <0x2c>;
				regulator-max-microvolt = <0x325aa0>;
				regulator-min-microvolt = <0x2dc6c0>;
				regulator-name = "vmch";
				status = "okay";
			};

			ldo_vrf18 {
				linux,phandle = <0x5d>;
				phandle = <0x5d>;
				regulator-default-on = <0x0>;
				regulator-enable-ramp-delay = <0xdc>;
				regulator-max-microvolt = <0x1b7740>;
				regulator-min-microvolt = <0x1b7740>;
				regulator-name = "vrf18";
				status = "okay";
			};

			ldo_vrtc {
				linux,phandle = <0x5b>;
				phandle = <0x5b>;
				regulator-enable-ramp-delay = <0x2c>;
				regulator-max-microvolt = <0x2ab980>;
				regulator-min-microvolt = <0x2ab980>;
				regulator-name = "vrtc";
			};

			ldo_vsim1 {
				linux,phandle = <0x53>;
				phandle = <0x53>;
				regulator-default-on = <0x0>;
				regulator-enable-ramp-delay = <0x108>;
				regulator-max-microvolt = <0x2dc6c0>;
				regulator-min-microvolt = <0x1b7740>;
				regulator-name = "vsim1";
				status = "okay";
			};

			ldo_vsim2 {
				linux,phandle = <0x54>;
				phandle = <0x54>;
				regulator-default-on = <0x0>;
				regulator-enable-ramp-delay = <0x108>;
				regulator-max-microvolt = <0x2dc6c0>;
				regulator-min-microvolt = <0x1b7740>;
				regulator-name = "vsim2";
				status = "okay";
			};

			ldo_vtcxo {
				linux,phandle = <0x50>;
				phandle = <0x50>;
				regulator-enable-ramp-delay = <0x6e>;
				regulator-max-microvolt = <0x2191c0>;
				regulator-min-microvolt = <0x2191c0>;
				regulator-name = "vtcxo";
			};

			ldo_vusb {
				linux,phandle = <0x55>;
				phandle = <0x55>;
				regulator-boot-on;
				regulator-enable-ramp-delay = <0x108>;
				regulator-max-microvolt = <0x325aa0>;
				regulator-min-microvolt = <0x325aa0>;
				regulator-name = "vusb";
			};

			vcanio_ldo_reg {
				linux,phandle = <0x35>;
				phandle = <0x35>;
				regulator-default-on = <0x0>;
				regulator-name = "vcanio";
				status = "okay";
			};

			vcn33_ldo_reg {
				regulator-default-on = <0x0>;
				regulator-name = "vcn33";
				status = "okay";
			};
		};

		regulators_supply {
			compatible = "mediatek,mt_pmic_regulator_supply";
			va-supply = <0x51>;
			vcamaf-supply = <0x34>;
			vcamd-supply = <0x33>;
			vcamio-supply = <0x5f>;
			vcn28-supply = <0x18>;
			vcn33_bt-supply = <0x19>;
			vcn33_wifi-supply = <0x1a>;
			vcn_1v8-supply = <0x17>;
			vemc_3v3-supply = <0x57>;
			vgp1-supply = <0xe>;
			vgp2-supply = <0x56>;
			vgp3-supply = <0x60>;
			vibr-supply = <0x5a>;
			vio18-supply = <0x5e>;
			vio28-supply = <0x52>;
			vm-supply = <0x5c>;
			vmc-supply = <0x58>;
			vmch-supply = <0x59>;
			vrf18-supply = <0x5d>;
			vrtc-supply = <0x5b>;
			vsim1-supply = <0x53>;
			vsim2-supply = <0x54>;
			vtcxo-supply = <0x50>;
			vusb-supply = <0x55>;
		};
	};

	mtk-msdc.0 {
		#address-cells = <0x1>;
		#size-cells = <0x1>;
		compatible = "simple-bus";
		ranges = <0x0 0x0 0x0 0xffffffff>;

		default {
			compatible = "mediatek,msdc1_ins-eint";
			debounce = <0x11 0x1f400>;
			interrupt-parent = <0xc>;
			interrupts = <0x11 0x8>;
			status = "okay";
		};

		msdc0@11120000 {
			bootable;
			bus-width = <0x8>;
			cap-mmc-highspeed;
			clk_src = [07];
			compatible = "mediatek,mt6580-mmc";
			host_function = [00];
			interrupts = <0x0 0x26 0x8>;
			max-frequency = <0xc65d400>;
			mmc-ddr-1_8v;
			mmc-hs200-1_8v;
			msdc-sys-suspend;
			non-removable;
			pinctl = <0x2>;
			reg = <0x11120000 0x10000 0x10001e84 0x2>;
			register_setting = <0x3>;
			status = "okay";
		};

		msdc1@11130000 {
			bus-width = <0x4>;
			cap-sd-highspeed;
			cd-gpios = <0x4 0x11 0x0>;
			cd_level = [00];
			clk_src = [02];
			compatible = "mediatek,mt6580-mmc";
			host_function = [01];
			interrupts = <0x0 0x27 0x8>;
			max-frequency = <0xc65d400>;
			msdc-sys-suspend;
			pinctl = <0x7>;
			pinctl_ddr50 = <0xa>;
			pinctl_sdr104 = <0x8>;
			pinctl_sdr50 = <0x9>;
			pinctrl-0 = <0x5>;
			pinctrl-1 = <0x6>;
			pinctrl-names = "default", "insert_cfg";
			reg = <0x11130000 0x10000 0x10001e84 0x2>;
			register_setting = <0xb>;
			sd-uhs-ddr50;
			sd-uhs-sdr104;
			sd-uhs-sdr12;
			sd-uhs-sdr25;
			sd-uhs-sdr50;
			status = "okay";
		};
	};

	pmu {
		compatible = "arm,cortex-a7-pmu";
		interrupts = <0x0 0x4 0x8 0x0 0x5 0x8 0x0 0x6 0x8 0x0 0x7 0x8>;
	};

	reserved-memory {
		#address-cells = <0x2>;
		#size-cells = <0x2>;
		ranges;

		consys-reserve-memory {
			alignment = <0x0 0x200000>;
			compatible = "mediatek,consys-reserve-memory";
			no-map;
			size = <0x0 0x200000>;
		};

		minirdump-reserved-memory@83ff0000 {
			compatible = "mediatek, minirdump";
			reg = <0x0 0x83ff0000 0x0 0x10000>;
		};

		pstore-reserved-memory@83f10000 {
			compatible = "mediatek,pstore";
			reg = <0x0 0x83f10000 0x0 0xe0000>;
		};

		ram_console-reserved-memory@83f00000 {
			compatible = "mediatek,ram_console";
			reg = <0x0 0x83f00000 0x0 0x10000>;
		};

		reserve-memory-ccci_md1 {
			alignment = <0x0 0x2000000>;
			alloc-ranges = <0x0 0x80000000 0x0 0x80000000>;
			compatible = "mediatek,reserve-memory-ccci_md1";
			no-map;
			size = <0x0 0x1800000>;
		};
	};

	rf_clock_buffer {
		#mediatek,clkbuf-config = <0x2 0x1 0x1 0x1>;
		#mediatek,clkbuf-quantity = <0x4>;
		compatible = "mediatek,rf_clock_buffer";
		mediatek,clkbuf-config = <0x2 0x2 0x1 0x1>;
		mediatek,clkbuf-quantity = <0x4>;
		status = "okay";
	};

	timer {
		clock-frequency = <0xc65d40>;
		compatible = "arm,armv7-timer";
		interrupts = <0x1 0xd 0x8 0x1 0xe 0x8 0x1 0xb 0x8 0x1 0xa 0x8>;
	};

	trusty {
		#address-cells = <0x2>;
		#size-cells = <0x2>;
		compatible = "android,trusty-smc-v1";
		ranges;

		irq {
			compatible = "android,trusty-irq-v1";
			ppi-interrupt-parent = <0x1>;
		};

		log {
			compatible = "android,trusty-log-v1";
		};

		mtee {
			compatible = "mediatek,trusty-mtee-v1";
		};

		virtio {
			compatible = "android,trusty-virtio-v1";
		};
	};

	vibrator@0 {
		compatible = "mediatek,vibrator";
		vib_limit = <0x9>;
		vib_timer = <0x19>;
		vib_vol = <0x6>;
	};
};
